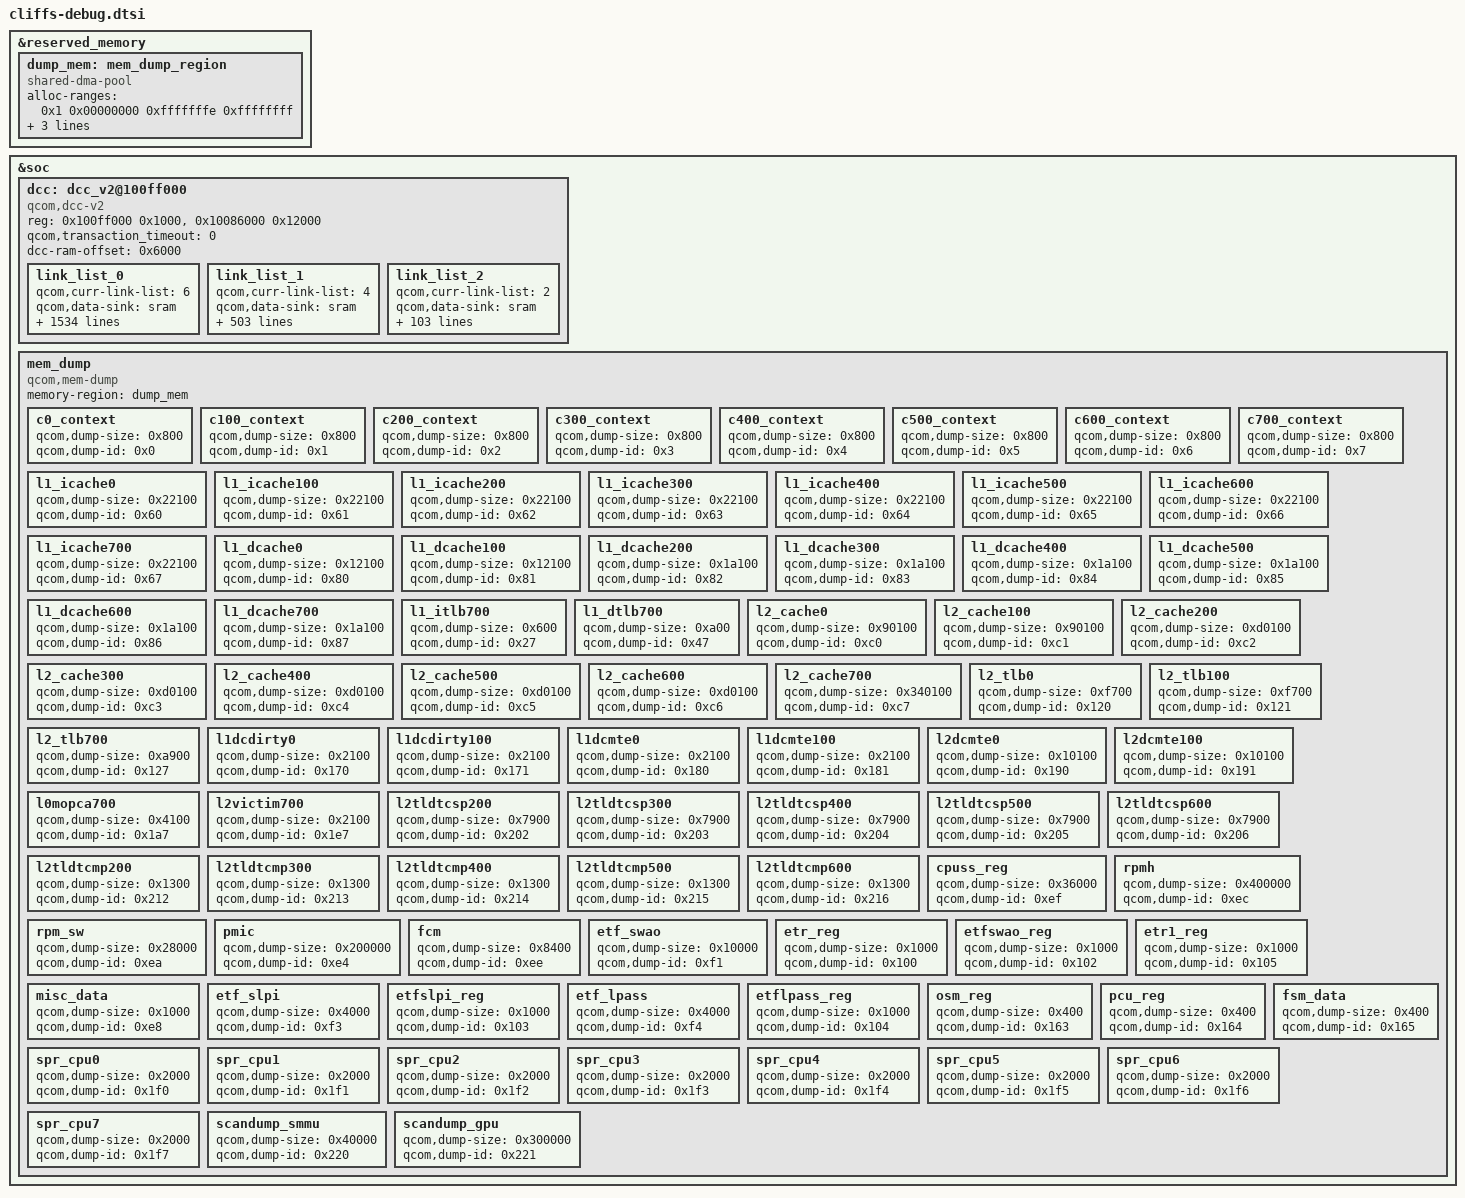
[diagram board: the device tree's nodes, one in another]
#include <dt-bindings/soc/qcom,dcc_v2.h>

&reserved_memory {
	#address-cells = <2>;
	#size-cells = <2>;
	ranges;

	dump_mem: mem_dump_region {
		compatible = "shared-dma-pool";
		alloc-ranges = <0x1 0x00000000 0xfffffffe 0xffffffff>;
		reusable;
		alignment = <0x0 0x400000>;
		size = <0 0x1800000>;
	};
};

&soc {
	dcc: dcc_v2@100ff000 {
		compatible = "qcom,dcc-v2";
		reg = <0x100ff000 0x1000>,
		      <0x10086000 0x12000>;

		qcom,transaction_timeout = <0>;

		reg-names = "dcc-base", "dcc-ram-base";
		dcc-ram-offset = <0x6000>;
		link_list_0 {
			qcom,curr-link-list = <6>;
			qcom,data-sink = "sram";
			qcom,ap-qad-override;
			qcom,link-list = <DCC_READ 0x17421000 2 0>,
				<DCC_READ 0x68c020c 2 0>,
				<DCC_READ 0x68c0228 3 0>,
				<DCC_READ 0x68c0248 3 0>,
				<DCC_READ 0x68c0268 3 0>,
				<DCC_READ 0x68c0288 3 0>,
				<DCC_READ 0x68c02a8 3 0>,
				<DCC_READ 0x68c0404 2 0>,
				<DCC_READ 0x720020c 2 0>,
				<DCC_READ 0x7200228 3 0>,
				<DCC_READ 0x7200248 3 0>,
				<DCC_READ 0x7200268 3 0>,
				<DCC_READ 0x7200288 3 0>,
				<DCC_READ 0x72002a8 3 0>,
				<DCC_READ 0x68c0110 1 0>,
				<DCC_READ 0x68c011c 1 0>,
				<DCC_READ 0x68c0208 1 0>,
				<DCC_READ 0x7200208 1 0>,
				<DCC_READ 0x320a4110 1 0>,
				<DCC_READ 0x320a411c 1 0>,
				<DCC_READ 0x320a4208 2 0>,
				<DCC_READ 0x320a4228 3 0>,
				<DCC_READ 0x320a4248 3 0>,
				<DCC_READ 0x320a4268 3 0>,
				<DCC_READ 0x320a4288 3 0>,
				<DCC_READ 0x320a42a8 3 0>,
				<DCC_READ 0x320a4400 3 0>,
				<DCC_READ 0x32302028 1 0>,
				<DCC_READ 0x323c0208 3 0>,
				<DCC_READ 0x323c0228 3 0>,
				<DCC_READ 0x323c0248 3 0>,
				<DCC_READ 0x323c0268 3 0>,
				<DCC_READ 0x323c0288 3 0>,
				<DCC_READ 0x323c02a8 3 0>,
				<DCC_READ 0x323c0400 3 0>,
				<DCC_READ 0x4080304 1 0>,
				<DCC_READ 0x4082028 1 0>,
				<DCC_READ 0x4140110 1 0>,
				<DCC_READ 0x414011c 1 0>,
				<DCC_READ 0x4140208 3 0>,
				<DCC_READ 0x4140228 3 0>,
				<DCC_READ 0x4140248 3 0>,
				<DCC_READ 0x4140268 3 0>,
				<DCC_READ 0x4140288 3 0>,
				<DCC_READ 0x41402a8 3 0>,
				<DCC_READ 0x4140400 3 0>,
				<DCC_READ 0x4200208 3 0>,
				<DCC_READ 0x4200228 3 0>,
				<DCC_READ 0x4200248 3 0>,
				<DCC_READ 0x4200268 3 0>,
				<DCC_READ 0x4200288 3 0>,
				<DCC_READ 0x42002a8 3 0>,
				<DCC_READ 0x4200400 3 0>,
				<DCC_READ 0x8a00304 1 0>,
				<DCC_READ 0x8a02028 1 0>,
				<DCC_READ 0x8ac011c 1 0>,
				<DCC_READ 0x8ac0208 3 0>,
				<DCC_READ 0x8ac0228 3 0>,
				<DCC_READ 0x8ac0248 3 0>,
				<DCC_READ 0x8ac0268 3 0>,
				<DCC_READ 0x8ac0288 3 0>,
				<DCC_READ 0x8ac02ac 2 0>,
				<DCC_READ 0x8ac02a8 1 0>,
				<DCC_READ 0x8ac0400 3 0>,
				<DCC_READ 0x8b00110 1 0>,
				<DCC_READ 0x6e0a100 1 0>,
				<DCC_READ 0x6e0a0ac 1 0>,
				<DCC_READ 0x6e0a0b0 1 0>,
				<DCC_READ 0x6e21104 1 0>,
				<DCC_READ 0x6e21108 1 0>,
				<DCC_READ 0x6e212ac 1 0>,
				<DCC_READ 0x6e212b0 1 0>,
				<DCC_READ 0x6e21300 1 0>,
				<DCC_READ 0x6e0a000 1 0>,
				<DCC_READ 0x7402048 1 0>,
				<DCC_READ 0x7402040 1 0>,
				<DCC_READ 0x1780005c 1 0>,
				<DCC_READ 0x1781005c 1 0>,
				<DCC_READ 0x1782005c 1 0>,
				<DCC_READ 0x1783005c 1 0>,
				<DCC_READ 0x1784005c 1 0>,
				<DCC_READ 0x1785005c 1 0>,
				<DCC_READ 0x1786005c 1 0>,
				<DCC_READ 0x1787005c 1 0>,
				<DCC_READ 0x1740003c 1 0>,
				<DCC_READ 0x17600238 1 0>,
				<DCC_READ 0x17600240 11 0>,
				<DCC_READ 0x17600274 1 0>,
				<DCC_READ 0x17600530 1 0>,
				<DCC_READ 0x1760051c 1 0>,
				<DCC_READ 0x17600524 1 0>,
				<DCC_READ 0x1760052c 1 0>,
				<DCC_READ 0x17600518 1 0>,
				<DCC_READ 0x17600520 1 0>,
				<DCC_READ 0x17600528 1 0>,
				<DCC_READ 0x17600404 4 0>,
				<DCC_READ 0x1760041c 4 0>,
				<DCC_READ 0x17600434 1 0>,
				<DCC_READ 0x1760043c 1 0>,
				<DCC_READ 0x17600440 1 0>,
				<DCC_READ 0x17400438 1 0>,
				<DCC_READ 0x17600044 1 0>,
				<DCC_READ 0x17600500 1 0>,
				<DCC_READ 0x221c209c 1 0>,
				<DCC_READ 0x17600504 5 0>,
				<DCC_READ 0x17900908 1 0>,
				<DCC_READ 0x17900c18 1 0>,
				<DCC_READ 0x17901908 1 0>,
				<DCC_READ 0x17901c18 1 0>,
				<DCC_READ 0x17b90810 3 0>,
				<DCC_READ 0x17b90c50 3 0>,
				<DCC_READ 0x17b93a04 2 0>,
				<DCC_READ 0x17ba0810 3 0>,
				<DCC_READ 0x17ba0c50 3 0>,
				<DCC_READ 0x17ba3a04 2 0>,
				<DCC_READ 0x17b93000 80 0>,
				<DCC_READ 0x17ba3000 80 0>,
				<DCC_READ 0x0c201244 1 0>,
				<DCC_READ 0x0c202244 1 0>,
				<DCC_READ 0x17b00000 1 0>,
				<DCC_READ 0x17a94030 1 0>,
				<DCC_READ 0x17a9408c 1 0>,
				<DCC_WRITE 0x17a9409c 0x78 0>,
				<DCC_WRITE 0x17a9409c 0x0 0>,
				<DCC_WRITE 0x17a94048 0x1 0>,
				<DCC_WRITE 0x17a94090 0x0 0>,
				<DCC_WRITE 0x17a94090 0x25 0>,
				<DCC_READ 0x17a94098 1 0>,
				<DCC_WRITE 0x17a94048 0x1d 0>,
				<DCC_WRITE 0x17a94090 0x0 0>,
				<DCC_WRITE 0x17a94090 0x25 0>,
				<DCC_READ 0x17a94098 1 0>,
				<DCC_READ 0x17a90030 1 0>,
				<DCC_READ 0x17a9008c 1 0>,
				<DCC_WRITE 0x17a9009c 0x78 0>,
				<DCC_WRITE 0x17a9009c 0x0 0>,
				<DCC_WRITE 0x17a90048 0x1 0>,
				<DCC_WRITE 0x17a90090 0x0 0>,
				<DCC_WRITE 0x17a90090 0x25 0>,
				<DCC_READ 0x17a90098 1 0>,
				<DCC_WRITE 0x17a90048 0x1d 0>,
				<DCC_WRITE 0x17a90090 0x0 0>,
				<DCC_WRITE 0x17a90090 0x25 0>,
				<DCC_READ 0x17a90098 1 0>,
				<DCC_READ 0x17a92030 1 0>,
				<DCC_READ 0x17a9208c 1 0>,
				<DCC_WRITE 0x17a9209c 0x78 0>,
				<DCC_WRITE 0x17a9209c 0x0 0>,
				<DCC_WRITE 0x17a92048 0x1 0>,
				<DCC_WRITE 0x17a92090 0x0 0>,
				<DCC_WRITE 0x17a92090 0x25 0>,
				<DCC_READ 0x17a92098 1 0>,
				<DCC_WRITE 0x17a92048 0x1d 0>,
				<DCC_WRITE 0x17a92090 0x0 0>,
				<DCC_WRITE 0x17a92090 0x25 0>,
				<DCC_READ 0x17a92098 1 0>,
				<DCC_READ 0x17a96030 1 0>,
				<DCC_READ 0x17a9608c 1 0>,
				<DCC_WRITE 0x17a9609c 0x78 0>,
				<DCC_WRITE 0x17a9609c 0x0 0>,
				<DCC_WRITE 0x17a96048 0x1 0>,
				<DCC_WRITE 0x17a96090 0x0 0>,
				<DCC_WRITE 0x17a96090 0x25 0>,
				<DCC_READ 0x17a96098 1 0>,
				<DCC_WRITE 0x17a96048 0x1d 0>,
				<DCC_WRITE 0x17a96090 0x0 0>,
				<DCC_WRITE 0x17a96090 0x25 0>,
				<DCC_READ 0x17a96098 1 0>,
				<DCC_READ 0x17d98024 1 0>,
				<DCC_READ 0x13822000 1 1>,
				<DCC_READ 0x221c20a4 1 0>,
				<DCC_READ 0x01fc8000 1 0>,
				<DCC_READ 0x17400038 1 0>,
				<DCC_READ 0x17d91020 1 0>,
				<DCC_READ 0x17d92020 1 0>,
				<DCC_READ 0x17d93020 1 0>,
				<DCC_READ 0x17d90020 1 0>,
				<DCC_READ 0x17d9134c 1 0>,
				<DCC_READ 0x17d9234c 1 0>,
				<DCC_READ 0x17d9334c 1 0>,
				<DCC_READ 0x17d9034c 1 0>,
				<DCC_READ 0x17d91300 1 0>,
				<DCC_READ 0x17d92300 1 0>,
				<DCC_READ 0x17d93300 1 0>,
				<DCC_READ 0x17d90300 1 0>,
				<DCC_READ 0x24183040 1 0>,
				<DCC_READ 0x24183048 1 0>,
				<DCC_READ 0x24102010 1 0>,
				<DCC_READ 0x24102020 6 0>,
				<DCC_READ 0x24102410 1 0>,
				<DCC_READ 0x24102420 6 0>,
				<DCC_READ 0x24142010 1 0>,
				<DCC_READ 0x24142020 6 0>,
				<DCC_READ 0x24142410 1 0>,
				<DCC_READ 0x24142420 6 0>,
				<DCC_READ 0x24182010 1 0>,
				<DCC_READ 0x24182020 6 0>,
				<DCC_READ 0x24182410 1 0>,
				<DCC_READ 0x24182420 6 0>,
				<DCC_READ 0x24102810 1 0>,
				<DCC_READ 0x24102820 1 0>,
				<DCC_READ 0x24102828 2 0>,
				<DCC_READ 0x24102C10 1 0>,
				<DCC_READ 0x24102C20 1 0>,
				<DCC_READ 0x24102C28 2 0>,
				<DCC_READ 0x24142810 1 0>,
				<DCC_READ 0x24142820 1 0>,
				<DCC_READ 0x24142828 2 0>,
				<DCC_READ 0x24142C10 1 0>,
				<DCC_READ 0x24142C20 1 0>,
				<DCC_READ 0x24142C28 2 0>,
				<DCC_READ 0x24100810 1 0>,
				<DCC_READ 0x24100838 1 0>,
				<DCC_READ 0x24100830 2 0>,
				<DCC_READ 0x24100830 2 0>,
				<DCC_READ 0x24100830 2 0>,
				<DCC_READ 0x24100830 2 0>,
				<DCC_READ 0x24100838 1 0>,
				<DCC_READ 0x24100830 2 0>,
				<DCC_READ 0x24100830 2 0>,
				<DCC_READ 0x24100830 2 0>,
				<DCC_READ 0x24100830 2 0>,
				<DCC_READ 0x24100838 1 0>,
				<DCC_READ 0x24100830 2 0>,
				<DCC_READ 0x24100830 2 0>,
				<DCC_READ 0x24100830 2 0>,
				<DCC_READ 0x24100830 2 0>,
				<DCC_READ 0x24100838 1 0>,
				<DCC_READ 0x24100830 2 0>,
				<DCC_READ 0x24100830 2 0>,
				<DCC_READ 0x24100830 2 0>,
				<DCC_READ 0x24100830 2 0>,
				<DCC_READ 0x24100808 2 0>,
				<DCC_READ 0x24100c10 1 0>,
				<DCC_READ 0x24100c38 1 0>,
				<DCC_READ 0x24100c30 2 0>,
				<DCC_READ 0x24100c30 2 0>,
				<DCC_READ 0x24100c30 2 0>,
				<DCC_READ 0x24100c30 2 0>,
				<DCC_READ 0x24100c38 1 0>,
				<DCC_READ 0x24100c30 2 0>,
				<DCC_READ 0x24100c30 2 0>,
				<DCC_READ 0x24100c30 2 0>,
				<DCC_READ 0x24100c30 2 0>,
				<DCC_READ 0x24100c38 1 0>,
				<DCC_READ 0x24100c30 2 0>,
				<DCC_READ 0x24100c30 2 0>,
				<DCC_READ 0x24100c30 2 0>,
				<DCC_READ 0x24100c30 2 0>,
				<DCC_READ 0x24100c38 1 0>,
				<DCC_READ 0x24100c30 2 0>,
				<DCC_READ 0x24100c30 2 0>,
				<DCC_READ 0x24100c30 2 0>,
				<DCC_READ 0x24100c30 2 0>,
				<DCC_READ 0x24100c08 2 0>,
				<DCC_READ 0x24140810 1 0>,
				<DCC_READ 0x24140838 1 0>,
				<DCC_READ 0x24140830 2 0>,
				<DCC_READ 0x24140830 2 0>,
				<DCC_READ 0x24140830 2 0>,
				<DCC_READ 0x24140830 2 0>,
				<DCC_READ 0x24140838 1 0>,
				<DCC_READ 0x24140830 2 0>,
				<DCC_READ 0x24140830 2 0>,
				<DCC_READ 0x24140830 2 0>,
				<DCC_READ 0x24140830 2 0>,
				<DCC_READ 0x24140838 1 0>,
				<DCC_READ 0x24140830 2 0>,
				<DCC_READ 0x24140830 2 0>,
				<DCC_READ 0x24140830 2 0>,
				<DCC_READ 0x24140830 2 0>,
				<DCC_READ 0x24140838 1 0>,
				<DCC_READ 0x24140830 2 0>,
				<DCC_READ 0x24140830 2 0>,
				<DCC_READ 0x24140830 2 0>,
				<DCC_READ 0x24140830 2 0>,
				<DCC_READ 0x24140808 2 0>,
				<DCC_READ 0x24140c10 1 0>,
				<DCC_READ 0x24140c38 1 0>,
				<DCC_READ 0x24140c30 2 0>,
				<DCC_READ 0x24140c30 2 0>,
				<DCC_READ 0x24140c30 2 0>,
				<DCC_READ 0x24140c30 2 0>,
				<DCC_READ 0x24140c38 1 0>,
				<DCC_READ 0x24140c30 2 0>,
				<DCC_READ 0x24140c30 2 0>,
				<DCC_READ 0x24140c30 2 0>,
				<DCC_READ 0x24140c30 2 0>,
				<DCC_READ 0x24140c38 1 0>,
				<DCC_READ 0x24140c30 2 0>,
				<DCC_READ 0x24140c30 2 0>,
				<DCC_READ 0x24140c30 2 0>,
				<DCC_READ 0x24140c30 2 0>,
				<DCC_READ 0x24140c38 1 0>,
				<DCC_READ 0x24140c30 2 0>,
				<DCC_READ 0x24140c30 2 0>,
				<DCC_READ 0x24140c30 2 0>,
				<DCC_READ 0x24140c30 2 0>,
				<DCC_READ 0x24140c08 2 0>,
				<DCC_READ 0x24180010 1 0>,
				<DCC_READ 0x24180038 1 0>,
				<DCC_READ 0x24180030 2 0>,
				<DCC_READ 0x24180030 2 0>,
				<DCC_READ 0x24180030 2 0>,
				<DCC_READ 0x24180030 2 0>,
				<DCC_READ 0x24180038 1 0>,
				<DCC_READ 0x24180030 2 0>,
				<DCC_READ 0x24180030 2 0>,
				<DCC_READ 0x24180030 2 0>,
				<DCC_READ 0x24180030 2 0>,
				<DCC_READ 0x24180038 1 0>,
				<DCC_READ 0x24180030 2 0>,
				<DCC_READ 0x24180030 2 0>,
				<DCC_READ 0x24180030 2 0>,
				<DCC_READ 0x24180030 2 0>,
				<DCC_READ 0x24180038 1 0>,
				<DCC_READ 0x24180030 2 0>,
				<DCC_READ 0x24180030 2 0>,
				<DCC_READ 0x24180030 2 0>,
				<DCC_READ 0x24180030 2 0>,
				<DCC_READ 0x24180008 2 0>,
				<DCC_READ 0x24180410 1 0>,
				<DCC_READ 0x24180438 1 0>,
				<DCC_READ 0x24180430 2 0>,
				<DCC_READ 0x24180430 2 0>,
				<DCC_READ 0x24180430 2 0>,
				<DCC_READ 0x24180430 2 0>,
				<DCC_READ 0x24180438 1 0>,
				<DCC_READ 0x24180430 2 0>,
				<DCC_READ 0x24180430 2 0>,
				<DCC_READ 0x24180430 2 0>,
				<DCC_READ 0x24180430 2 0>,
				<DCC_READ 0x24180438 1 0>,
				<DCC_READ 0x24180430 2 0>,
				<DCC_READ 0x24180430 2 0>,
				<DCC_READ 0x24180430 2 0>,
				<DCC_READ 0x24180430 2 0>,
				<DCC_READ 0x24180438 1 0>,
				<DCC_READ 0x24180430 2 0>,
				<DCC_READ 0x24180430 2 0>,
				<DCC_READ 0x24180430 2 0>,
				<DCC_READ 0x24180430 2 0>,
				<DCC_READ 0x24180408 2 0>,
				<DCC_READ 0x24101000 3 0>,
				<DCC_READ 0x24101010 2 0>,
				<DCC_READ 0x24101010 2 0>,
				<DCC_READ 0x24101018 1 0>,
				<DCC_READ 0x24101080 1 0>,
				<DCC_READ 0x24101084 2 0>,
				<DCC_LOOP 0x5 0 0>,
				<DCC_READ 0x24101090 2 0>,
				<DCC_LOOP 0x1 0 0>,
				<DCC_READ 0x24101098 1 0>,
				<DCC_READ 0x24141000 1 0>,
				<DCC_READ 0x24141004 2 0>,
				<DCC_READ 0x24141010 2 0>,
				<DCC_READ 0x24141010 2 0>,
				<DCC_READ 0x24141018 1 0>,
				<DCC_READ 0x24141080 1 0>,
				<DCC_READ 0x24141084 1 0>,
				<DCC_LOOP 0x5 0 0>,
				<DCC_READ 0x24141090 2 0>,
				<DCC_LOOP 0x1 0 0>,
				<DCC_READ 0x24141098 1 0>,
				<DCC_READ 0x24181000 1 0>,
				<DCC_READ 0x24181004 2 0>,
				<DCC_READ 0x24181010 2 0>,
				<DCC_READ 0x24181010 2 0>,
				<DCC_READ 0x24181018 1 0>,
				<DCC_READ 0x24181080 1 0>,
				<DCC_READ 0x24181084 2 0>,
				<DCC_LOOP 0xb 0 0>,
				<DCC_READ 0x24181090 2 0>,
				<DCC_LOOP 0x1 0 0>,
				<DCC_READ 0x24181098 1 0>,
				<DCC_READ 0x24131010 1 0>,
				<DCC_READ 0x24133010 1 0>,
				<DCC_READ 0x24135010 1 0>,
				<DCC_READ 0x24137010 1 0>,
				<DCC_READ 0x24138010 1 0>,
				<DCC_READ 0x24139010 1 0>,
				<DCC_READ 0x24171010 1 0>,
				<DCC_READ 0x24173010 1 0>,
				<DCC_READ 0x24175010 1 0>,
				<DCC_READ 0x24177010 1 0>,
				<DCC_READ 0x24178010 1 0>,
				<DCC_READ 0x24179010 1 0>,
				<DCC_READ 0x241b1010 1 0>,
				<DCC_READ 0x241b3010 1 0>,
				<DCC_READ 0x241b5010 1 0>,
				<DCC_READ 0x241b7010 1 0>,
				<DCC_READ 0x241b9010 1 0>,
				<DCC_READ 0x241bb010 1 0>,
				<DCC_READ 0x241bc010 1 0>,
				<DCC_READ 0x241bd010 1 0>,
				<DCC_READ 0x241bf010 1 0>,
				<DCC_READ 0x241c1010 1 0>,
				<DCC_READ 0x241c3010 1 0>,
				<DCC_WRITE 0x24100828 0x2 0>,
				<DCC_LOOP 0x40 0 0>,
				<DCC_READ 0x24100830 2 0>,
				<DCC_READ 0x24100830 2 0>,
				<DCC_READ 0x24100830 2 0>,
				<DCC_READ 0x24100830 2 0>,
				<DCC_LOOP 0x1 0 0>,
				<DCC_WRITE 0x24100828 0x1 0>,
				<DCC_WRITE 0x24100c28 0x2 0>,
				<DCC_LOOP 0x40 0 0>,
				<DCC_READ 0x24100c30 2 0>,
				<DCC_READ 0x24100c30 2 0>,
				<DCC_READ 0x24100c30 2 0>,
				<DCC_READ 0x24100c30 2 0>,
				<DCC_LOOP 0x1 0 0>,
				<DCC_WRITE 0x24100c28 0x1 0>,
				<DCC_WRITE 0x24140828 0x2 0>,
				<DCC_LOOP 0x40 0 0>,
				<DCC_READ 0x24140830 2 0>,
				<DCC_READ 0x24140830 2 0>,
				<DCC_READ 0x24140830 2 0>,
				<DCC_READ 0x24140830 2 0>,
				<DCC_LOOP 0x1 0 0>,
				<DCC_WRITE 0x24140828 0x1 0>,
				<DCC_WRITE 0x24140c28 0x2 0>,
				<DCC_LOOP 0x40 0 0>,
				<DCC_READ 0x24140c30 2 0>,
				<DCC_READ 0x24140c30 2 0>,
				<DCC_READ 0x24140c30 2 0>,
				<DCC_READ 0x24140c30 2 0>,
				<DCC_LOOP 0x1 0 0>,
				<DCC_WRITE 0x24140c28 0x1 0>,
				<DCC_READ 0x17810024 1 0>,
				<DCC_READ 0x17810038 6 0>,
				<DCC_READ 0x17810058 4 0>,
				<DCC_READ 0x1781006c 1 0>,
				<DCC_READ 0x178100f0 2 0>,
				<DCC_READ 0x17820010 1 0>,
				<DCC_READ 0x17820024 1 0>,
				<DCC_READ 0x17820038 6 0>,
				<DCC_READ 0x17820058 4 0>,
				<DCC_READ 0x178200f0 2 0>,
				<DCC_READ 0x17830010 1 0>,
				<DCC_READ 0x17830024 1 0>,
				<DCC_READ 0x17830038 6 0>,
				<DCC_READ 0x17830058 4 0>,
				<DCC_READ 0x178300f0 2 0>,
				<DCC_READ 0x17840010 1 0>,
				<DCC_READ 0x17840024 1 0>,
				<DCC_READ 0x17840038 6 0>,
				<DCC_READ 0x17840058 4 0>,
				<DCC_READ 0x178400f0 2 0>,
				<DCC_READ 0x17850010 1 0>,
				<DCC_READ 0x17850024 1 0>,
				<DCC_READ 0x17850038 6 0>,
				<DCC_READ 0x17850058 4 0>,
				<DCC_READ 0x178500f0 2 0>,
				<DCC_READ 0x17860010 1 0>,
				<DCC_READ 0x17860024 1 0>,
				<DCC_READ 0x17860038 6 0>,
				<DCC_READ 0x17860058 4 0>,
				<DCC_READ 0x178600f0 2 0>,
				<DCC_READ 0x17870010 1 0>,
				<DCC_READ 0x17870024 1 0>,
				<DCC_READ 0x17870038 6 0>,
				<DCC_READ 0x17870058 4 0>,
				<DCC_READ 0x178700f0 2 0>,
				<DCC_READ 0x17880010 1 0>,
				<DCC_READ 0x17880024 1 0>,
				<DCC_READ 0x17880038 6 0>,
				<DCC_READ 0x17890010 1 0>,
				<DCC_READ 0x17890024 1 0>,
				<DCC_READ 0x17890038 6 0>,
				<DCC_READ 0x178b0010 1 0>,
				<DCC_READ 0x178b0024 1 0>,
				<DCC_READ 0x178b0038 6 0>,
				<DCC_READ 0x178b006c 5 0>,
				<DCC_READ 0x178b0084 1 0>,
				<DCC_READ 0x178b00f4 5 0>,
				<DCC_READ 0x178b0118 9 0>,
				<DCC_READ 0x178b0158 5 0>,
				<DCC_READ 0x178b0170 2 0>,
				<DCC_READ 0x178b0188 5 0>,
				<DCC_READ 0x178b01ac 6 0>,
				<DCC_READ 0x178b01c8 1 0>,
				<DCC_READ 0x178b0204 1 0>,
				<DCC_READ 0x178b0244 1 0>,
				<DCC_READ 0x17e30000 1 0>,
				<DCC_READ 0x17e30008 1 0>,
				<DCC_READ 0x17e30010 1 0>,
				<DCC_READ 0x17e80000 1 0>,
				<DCC_READ 0x17e80008 1 0>,
				<DCC_READ 0x17e80010 1 0>,
				<DCC_READ 0x17f80000 1 0>,
				<DCC_READ 0x17f80008 1 0>,
				<DCC_READ 0x17f80010 1 0>,
				<DCC_READ 0x18080000 1 0>,
				<DCC_READ 0x18080008 1 0>,
				<DCC_READ 0x18080010 1 0>,
				<DCC_READ 0x18180000 1 0>,
				<DCC_READ 0x18180008 1 0>,
				<DCC_READ 0x18180010 1 0>,
				<DCC_READ 0x18280000 1 0>,
				<DCC_READ 0x18280008 1 0>,
				<DCC_READ 0x18280010 1 0>,
				<DCC_READ 0x18380000 1 0>,
				<DCC_READ 0x18380008 1 0>,
				<DCC_READ 0x18380010 1 0>,
				<DCC_READ 0x18480000 1 0>,
				<DCC_READ 0x18480008 1 0>,
				<DCC_READ 0x18480010 1 0>,
				<DCC_READ 0x18580000 1 0>,
				<DCC_READ 0x18580008 1 0>,
				<DCC_READ 0x18580010 1 0>,
				<DCC_READ 0x2407701c 1 0>,
				<DCC_READ 0x24077030 1 0>,
				<DCC_READ 0x2408005c 1 0>,
				<DCC_READ 0x240800c8 1 0>,
				<DCC_READ 0x240800d4 1 0>,
				<DCC_READ 0x240800e0 1 0>,
				<DCC_READ 0x240800ec 1 0>,
				<DCC_READ 0x240800f8 1 0>,
				<DCC_READ 0x240801b4 1 0>,
				<DCC_READ 0x240a8120 5 0>,
				<DCC_READ 0x240a8144 2 0>,
				<DCC_READ 0x240a81d0 4 0>,
				<DCC_READ 0x240a81f0 1 0>,
				<DCC_READ 0x240a81fc 1 0>,
				<DCC_READ 0x240a8208 1 0>,
				<DCC_READ 0x240a8214 1 0>,
				<DCC_READ 0x240a8264 1 0>,
				<DCC_READ 0x240a8284 1 0>,
				<DCC_READ 0x240a82fc 1 0>,
				<DCC_READ 0x240a8860 3 0>,
				<DCC_READ 0x240aa034 3 0>,
				<DCC_READ 0x240ba28c 1 0>,
				<DCC_READ 0x240ba294 1 0>,
				<DCC_READ 0x240ba29c 1 0>,
				<DCC_READ 0x24185100 4 0>,
				<DCC_READ 0x24187100 1 0>,
				<DCC_READ 0x2418c100 1 0>,
				<DCC_READ 0x24401e64 1 0>,
				<DCC_READ 0x24401ea0 1 0>,
				<DCC_READ 0x24403e64 1 0>,
				<DCC_READ 0x24403ea0 1 0>,
				<DCC_READ 0x2440527c 1 0>,
				<DCC_READ 0x24405290 1 0>,
				<DCC_READ 0x244054ec 1 0>,
				<DCC_READ 0x244054f4 1 0>,
				<DCC_READ 0x24405514 1 0>,
				<DCC_READ 0x2440551c 1 0>,
				<DCC_READ 0x24405524 1 0>,
				<DCC_READ 0x24405548 1 0>,
				<DCC_READ 0x24405550 1 0>,
				<DCC_READ 0x24405558 1 0>,
				<DCC_READ 0x244055b8 1 0>,
				<DCC_READ 0x244055c0 1 0>,
				<DCC_READ 0x244055ec 1 0>,
				<DCC_READ 0x24405870 1 0>,
				<DCC_READ 0x244058a0 1 0>,
				<DCC_READ 0x244058a8 1 0>,
				<DCC_READ 0x244058b0 1 0>,
				<DCC_READ 0x244058b8 1 0>,
				<DCC_READ 0x244058d8 2 0>,
				<DCC_READ 0x244058f4 1 0>,
				<DCC_READ 0x244058fc 1 0>,
				<DCC_READ 0x24405920 1 0>,
				<DCC_READ 0x24405928 1 0>,
				<DCC_READ 0x24405944 1 0>,
				<DCC_READ 0x24406604 1 0>,
				<DCC_READ 0x2440660c 1 0>,
				<DCC_READ 0x24440310 1 0>,
				<DCC_READ 0x24440400 2 0>,
				<DCC_READ 0x24440410 3 0>,
				<DCC_READ 0x24440428 1 0>,
				<DCC_READ 0x24440430 1 0>,
				<DCC_READ 0x24440440 1 0>,
				<DCC_READ 0x24440448 1 0>,
				<DCC_READ 0x244404a0 1 0>,
				<DCC_READ 0x244404b0 3 0>,
				<DCC_READ 0x244404d0 2 0>,
				<DCC_READ 0x2444341c 1 0>,
				<DCC_READ 0x24445804 1 0>,
				<DCC_READ 0x2444590c 1 0>,
				<DCC_READ 0x24445a14 1 0>,
				<DCC_READ 0x24445c1c 1 0>,
				<DCC_READ 0x24445c38 1 0>,
				<DCC_READ 0x24449100 1 0>,
				<DCC_READ 0x24449110 1 0>,
				<DCC_READ 0x24449120 1 0>,
				<DCC_READ 0x24449180 2 0>,
				<DCC_READ 0x24460618 1 0>,
				<DCC_READ 0x24460684 1 0>,
				<DCC_READ 0x2446068c 1 0>,
				<DCC_READ 0x24481e64 1 0>,
				<DCC_READ 0x24481ea0 1 0>,
				<DCC_READ 0x24483e64 1 0>,
				<DCC_READ 0x24483ea0 1 0>,
				<DCC_READ 0x2448527c 1 0>,
				<DCC_READ 0x24485290 1 0>,
				<DCC_READ 0x244854ec 1 0>,
				<DCC_READ 0x244854f4 1 0>,
				<DCC_READ 0x24485514 1 0>,
				<DCC_READ 0x2448551c 1 0>,
				<DCC_READ 0x24485524 1 0>,
				<DCC_READ 0x24485548 1 0>,
				<DCC_READ 0x24485550 1 0>,
				<DCC_READ 0x24485558 1 0>,
				<DCC_READ 0x244855b8 1 0>,
				<DCC_READ 0x244855c0 1 0>,
				<DCC_READ 0x244855ec 1 0>,
				<DCC_READ 0x24485870 1 0>,
				<DCC_READ 0x244858a0 1 0>,
				<DCC_READ 0x244858a8 1 0>,
				<DCC_READ 0x244858b0 1 0>,
				<DCC_READ 0x244858b8 1 0>,
				<DCC_READ 0x244858d8 2 0>,
				<DCC_READ 0x244858f4 1 0>,
				<DCC_READ 0x244858fc 1 0>,
				<DCC_READ 0x24485920 1 0>,
				<DCC_READ 0x24485928 1 0>,
				<DCC_READ 0x24485944 1 0>,
				<DCC_READ 0x24486604 1 0>,
				<DCC_READ 0x2448660c 1 0>,
				<DCC_READ 0x244c0310 1 0>,
				<DCC_READ 0x244c0400 2 0>,
				<DCC_READ 0x244c0410 3 0>,
				<DCC_READ 0x244c0428 1 0>,
				<DCC_READ 0x244c0430 1 0>,
				<DCC_READ 0x244c0440 1 0>,
				<DCC_READ 0x244c0448 1 0>,
				<DCC_READ 0x244c04a0 1 0>,
				<DCC_READ 0x244c04b0 3 0>,
				<DCC_READ 0x244c04d0 2 0>,
				<DCC_READ 0x244c341c 1 0>,
				<DCC_READ 0x244c5804 1 0>,
				<DCC_READ 0x244c590c 1 0>,
				<DCC_READ 0x244c5a14 1 0>,
				<DCC_READ 0x244c5c1c 1 0>,
				<DCC_READ 0x244c5c38 1 0>,
				<DCC_READ 0x244c9100 1 0>,
				<DCC_READ 0x244c9110 1 0>,
				<DCC_READ 0x244c9120 1 0>,
				<DCC_READ 0x244c9180 2 0>,
				<DCC_READ 0x244e0618 1 0>,
				<DCC_READ 0x244e0684 1 0>,
				<DCC_READ 0x244e068c 1 0>,
				<DCC_READ 0x24601e64 1 0>,
				<DCC_READ 0x24601ea0 1 0>,
				<DCC_READ 0x24603e64 1 0>,
				<DCC_READ 0x24603ea0 1 0>,
				<DCC_READ 0x2460527c 1 0>,
				<DCC_READ 0x24605290 1 0>,
				<DCC_READ 0x246054ec 1 0>,
				<DCC_READ 0x246054f4 1 0>,
				<DCC_READ 0x24605514 1 0>,
				<DCC_READ 0x2460551c 1 0>,
				<DCC_READ 0x24605524 1 0>,
				<DCC_READ 0x24605548 1 0>,
				<DCC_READ 0x24605550 1 0>,
				<DCC_READ 0x24605558 1 0>,
				<DCC_READ 0x246055b8 1 0>,
				<DCC_READ 0x246055c0 1 0>,
				<DCC_READ 0x246055ec 1 0>,
				<DCC_READ 0x24605870 1 0>,
				<DCC_READ 0x246058a0 1 0>,
				<DCC_READ 0x246058a8 1 0>,
				<DCC_READ 0x246058b0 1 0>,
				<DCC_READ 0x246058b8 1 0>,
				<DCC_READ 0x246058d8 2 0>,
				<DCC_READ 0x246058f4 1 0>,
				<DCC_READ 0x246058fc 1 0>,
				<DCC_READ 0x24605920 1 0>,
				<DCC_READ 0x24605928 1 0>,
				<DCC_READ 0x24605944 1 0>,
				<DCC_READ 0x24606604 1 0>,
				<DCC_READ 0x2460660c 1 0>,
				<DCC_READ 0x24640310 1 0>,
				<DCC_READ 0x24640400 2 0>,
				<DCC_READ 0x24640410 3 0>,
				<DCC_READ 0x24640428 1 0>,
				<DCC_READ 0x24640430 1 0>,
				<DCC_READ 0x24640440 1 0>,
				<DCC_READ 0x24640448 1 0>,
				<DCC_READ 0x246404a0 1 0>,
				<DCC_READ 0x246404b0 3 0>,
				<DCC_READ 0x246404d0 2 0>,
				<DCC_READ 0x2464341c 1 0>,
				<DCC_READ 0x24645804 1 0>,
				<DCC_READ 0x2464590c 1 0>,
				<DCC_READ 0x24645a14 1 0>,
				<DCC_READ 0x24645c1c 1 0>,
				<DCC_READ 0x24645c38 1 0>,
				<DCC_READ 0x24649100 1 0>,
				<DCC_READ 0x24649110 1 0>,
				<DCC_READ 0x24649120 1 0>,
				<DCC_READ 0x24649180 2 0>,
				<DCC_READ 0x24660618 1 0>,
				<DCC_READ 0x24660684 1 0>,
				<DCC_READ 0x2466068c 1 0>,
				<DCC_READ 0x24681e64 1 0>,
				<DCC_READ 0x24681ea0 1 0>,
				<DCC_READ 0x24683e64 1 0>,
				<DCC_READ 0x24683ea0 1 0>,
				<DCC_READ 0x2468527c 1 0>,
				<DCC_READ 0x24685290 1 0>,
				<DCC_READ 0x246854ec 1 0>,
				<DCC_READ 0x246854f4 1 0>,
				<DCC_READ 0x24685514 1 0>,
				<DCC_READ 0x2468551c 1 0>,
				<DCC_READ 0x24685524 1 0>,
				<DCC_READ 0x24685548 1 0>,
				<DCC_READ 0x24685550 1 0>,
				<DCC_READ 0x24685558 1 0>,
				<DCC_READ 0x246855b8 1 0>,
				<DCC_READ 0x246855c0 1 0>,
				<DCC_READ 0x246855ec 1 0>,
				<DCC_READ 0x24685870 1 0>,
				<DCC_READ 0x246858a0 1 0>,
				<DCC_READ 0x246858a8 1 0>,
				<DCC_READ 0x246858b0 1 0>,
				<DCC_READ 0x246858b8 1 0>,
				<DCC_READ 0x246858d8 2 0>,
				<DCC_READ 0x246858f4 1 0>,
				<DCC_READ 0x246858fc 1 0>,
				<DCC_READ 0x24685920 1 0>,
				<DCC_READ 0x24685928 1 0>,
				<DCC_READ 0x24685944 1 0>,
				<DCC_READ 0x24686604 1 0>,
				<DCC_READ 0x2468660c 1 0>,
				<DCC_READ 0x246c0310 1 0>,
				<DCC_READ 0x246c0400 2 0>,
				<DCC_READ 0x246c0410 3 0>,
				<DCC_READ 0x246c0428 1 0>,
				<DCC_READ 0x246c0430 1 0>,
				<DCC_READ 0x246c0440 1 0>,
				<DCC_READ 0x246c0448 1 0>,
				<DCC_READ 0x246c04a0 1 0>,
				<DCC_READ 0x246c04b0 3 0>,
				<DCC_READ 0x246c04d0 2 0>,
				<DCC_READ 0x246c341c 1 0>,
				<DCC_READ 0x246c5804 1 0>,
				<DCC_READ 0x246c590c 1 0>,
				<DCC_READ 0x246c5a14 1 0>,
				<DCC_READ 0x246c5c1c 1 0>,
				<DCC_READ 0x246c5c38 1 0>,
				<DCC_READ 0x246c9100 1 0>,
				<DCC_READ 0x246c9110 1 0>,
				<DCC_READ 0x246c9120 1 0>,
				<DCC_READ 0x246c9180 2 0>,
				<DCC_READ 0x246e0618 1 0>,
				<DCC_READ 0x246e0684 1 0>,
				<DCC_READ 0x246e068c 1 0>,
				<DCC_READ 0x24840310 1 0>,
				<DCC_READ 0x24840400 2 0>,
				<DCC_READ 0x24840410 3 0>,
				<DCC_READ 0x24840428 1 0>,
				<DCC_READ 0x24840430 1 0>,
				<DCC_READ 0x24840440 1 0>,
				<DCC_READ 0x24840448 1 0>,
				<DCC_READ 0x248404a0 1 0>,
				<DCC_READ 0x248404b0 3 0>,
				<DCC_READ 0x248404d0 2 0>,
				<DCC_READ 0x2484341c 1 0>,
				<DCC_READ 0x24845804 1 0>,
				<DCC_READ 0x2484590c 1 0>,
				<DCC_READ 0x24845a14 1 0>,
				<DCC_READ 0x24845c1c 1 0>,
				<DCC_READ 0x24845c38 1 0>,
				<DCC_READ 0x24849100 1 0>,
				<DCC_READ 0x24849110 1 0>,
				<DCC_READ 0x24849120 1 0>,
				<DCC_READ 0x24849180 2 0>,
				<DCC_READ 0x24860618 1 0>,
				<DCC_READ 0x24860684 1 0>,
				<DCC_READ 0x2486068c 1 0>,
				<DCC_READ 0x248c0310 1 0>,
				<DCC_READ 0x248c0400 2 0>,
				<DCC_READ 0x248c0410 3 0>,
				<DCC_READ 0x248c0428 1 0>,
				<DCC_READ 0x248c0430 1 0>,
				<DCC_READ 0x248c0440 1 0>,
				<DCC_READ 0x248c0448 1 0>,
				<DCC_READ 0x248c04a0 1 0>,
				<DCC_READ 0x248c04b0 3 0>,
				<DCC_READ 0x248c04d0 2 0>,
				<DCC_READ 0x248c341c 1 0>,
				<DCC_READ 0x248c5804 1 0>,
				<DCC_READ 0x248c590c 1 0>,
				<DCC_READ 0x248c5a14 1 0>,
				<DCC_READ 0x248c5c1c 1 0>,
				<DCC_READ 0x248c5c38 1 0>,
				<DCC_READ 0x248c9100 1 0>,
				<DCC_READ 0x248c9110 1 0>,
				<DCC_READ 0x248c9120 1 0>,
				<DCC_READ 0x248c9180 2 0>,
				<DCC_READ 0x248e0618 1 0>,
				<DCC_READ 0x248e0684 1 0>,
				<DCC_READ 0x248e068c 1 0>,
				<DCC_READ 0x25020348 1 0>,
				<DCC_READ 0x25020480 1 0>,
				<DCC_READ 0x25022400 1 0>,
				<DCC_READ 0x25023220 4 0>,
				<DCC_READ 0x25023308 1 0>,
				<DCC_READ 0x25023318 1 0>,
				<DCC_READ 0x25038100 1 0>,
				<DCC_READ 0x2503c030 1 0>,
				<DCC_READ 0x25042044 3 0>,
				<DCC_READ 0x250420b0 1 0>,
				<DCC_READ 0x25042104 1 0>,
				<DCC_READ 0x25042114 1 0>,
				<DCC_READ 0x25048004 5 0>,
				<DCC_READ 0x2504c030 1 0>,
				<DCC_READ 0x25050020 1 0>,
				<DCC_READ 0x2506004c 8 0>,
				<DCC_READ 0x25220348 1 0>,
				<DCC_READ 0x25220480 1 0>,
				<DCC_READ 0x25222400 1 0>,
				<DCC_READ 0x25223220 4 0>,
				<DCC_READ 0x25223308 1 0>,
				<DCC_READ 0x25223318 1 0>,
				<DCC_READ 0x25238100 1 0>,
				<DCC_READ 0x2523c030 1 0>,
				<DCC_READ 0x25242044 3 0>,
				<DCC_READ 0x252420b0 1 0>,
				<DCC_READ 0x25242104 1 0>,
				<DCC_READ 0x25242114 1 0>,
				<DCC_READ 0x25248004 5 0>,
				<DCC_READ 0x2524c030 1 0>,
				<DCC_READ 0x25250020 1 0>,
				<DCC_READ 0x2526004c 8 0>,
				<DCC_READ 0x25420348 1 0>,
				<DCC_READ 0x25420480 1 0>,
				<DCC_READ 0x25422400 1 0>,
				<DCC_READ 0x25423220 4 0>,
				<DCC_READ 0x25423308 1 0>,
				<DCC_READ 0x25423318 1 0>,
				<DCC_READ 0x25438100 1 0>,
				<DCC_READ 0x2543c030 1 0>,
				<DCC_READ 0x25442044 3 0>,
				<DCC_READ 0x254420b0 1 0>,
				<DCC_READ 0x25442104 1 0>,
				<DCC_READ 0x25442114 1 0>,
				<DCC_READ 0x25448004 5 0>,
				<DCC_READ 0x2544c030 1 0>,
				<DCC_READ 0x25450020 1 0>,
				<DCC_READ 0x2546004c 8 0>,
				<DCC_READ 0x25620348 1 0>,
				<DCC_READ 0x25620480 1 0>,
				<DCC_READ 0x25622400 1 0>,
				<DCC_READ 0x25623220 4 0>,
				<DCC_READ 0x25623308 1 0>,
				<DCC_READ 0x25623318 1 0>,
				<DCC_READ 0x25638100 1 0>,
				<DCC_READ 0x2563c030 1 0>,
				<DCC_READ 0x25642044 3 0>,
				<DCC_READ 0x256420b0 1 0>,
				<DCC_READ 0x25642104 1 0>,
				<DCC_READ 0x25642114 1 0>,
				<DCC_READ 0x25648004 5 0>,
				<DCC_READ 0x2564c030 1 0>,
				<DCC_READ 0x25650020 1 0>,
				<DCC_READ 0x2566004c 8 0>,
				<DCC_READ 0x25820348 1 0>,
				<DCC_READ 0x25820480 1 0>,
				<DCC_READ 0x25822400 1 0>,
				<DCC_READ 0x25823220 4 0>,
				<DCC_READ 0x25823308 1 0>,
				<DCC_READ 0x25823318 1 0>,
				<DCC_READ 0x25838100 1 0>,
				<DCC_READ 0x2583c030 1 0>,
				<DCC_READ 0x25842044 3 0>,
				<DCC_READ 0x258420b0 1 0>,
				<DCC_READ 0x25842104 1 0>,
				<DCC_READ 0x25842114 1 0>,
				<DCC_READ 0x25848004 5 0>,
				<DCC_READ 0x2584c030 1 0>,
				<DCC_READ 0x25850020 1 0>,
				<DCC_READ 0x2586004c 8 0>,
				<DCC_READ 0x25a20348 1 0>,
				<DCC_READ 0x25a20480 1 0>,
				<DCC_READ 0x25a22400 1 0>,
				<DCC_READ 0x25a23220 4 0>,
				<DCC_READ 0x25a23308 1 0>,
				<DCC_READ 0x25a23318 1 0>,
				<DCC_READ 0x25a38100 1 0>,
				<DCC_READ 0x25a3c030 1 0>,
				<DCC_READ 0x25a42044 3 0>,
				<DCC_READ 0x25a420b0 1 0>,
				<DCC_READ 0x25a42104 1 0>,
				<DCC_READ 0x25a42114 1 0>,
				<DCC_READ 0x25a48004 5 0>,
				<DCC_READ 0x25a4c030 1 0>,
				<DCC_READ 0x25a50020 1 0>,
				<DCC_READ 0x25a6004c 8 0>,
				<DCC_READ 0x25000004 1 0>,
				<DCC_READ 0x25001004 1 0>,
				<DCC_READ 0x25002004 1 0>,
				<DCC_READ 0x25003004 1 0>,
				<DCC_READ 0x25004004 1 0>,
				<DCC_READ 0x25005004 1 0>,
				<DCC_READ 0x25006004 1 0>,
				<DCC_READ 0x25007004 1 0>,
				<DCC_READ 0x25008004 1 0>,
				<DCC_READ 0x25009004 1 0>,
				<DCC_READ 0x2500a004 1 0>,
				<DCC_READ 0x2500b004 1 0>,
				<DCC_READ 0x2500c004 1 0>,
				<DCC_READ 0x2500d004 1 0>,
				<DCC_READ 0x2500e004 1 0>,
				<DCC_READ 0x2500f004 1 0>,
				<DCC_READ 0x25010004 1 0>,
				<DCC_READ 0x25011004 1 0>,
				<DCC_READ 0x25012004 1 0>,
				<DCC_READ 0x25013004 1 0>,
				<DCC_READ 0x25014004 1 0>,
				<DCC_READ 0x25015004 1 0>,
				<DCC_READ 0x25016004 1 0>,
				<DCC_READ 0x25017004 1 0>,
				<DCC_READ 0x25018004 1 0>,
				<DCC_READ 0x25019004 1 0>,
				<DCC_READ 0x2501a004 1 0>,
				<DCC_READ 0x2501b004 1 0>,
				<DCC_READ 0x2501c004 1 0>,
				<DCC_READ 0x2501d004 1 0>,
				<DCC_READ 0x2501e004 1 0>,
				<DCC_READ 0x2501f004 1 0>,
				<DCC_READ 0x2507601c 4 0>,
				<DCC_READ 0x25076034 4 0>,
				<DCC_READ 0x25076058 1 0>,
				<DCC_READ 0x25076200 1 0>,
				<DCC_READ 0x25077020 1 0>,
				<DCC_READ 0x25077030 20 0>,
				<DCC_READ 0x25077084 1 0>,
				<DCC_READ 0x25077090 5 0>,
				<DCC_READ 0x25077218 8 0>,
				<DCC_READ 0x250a002c 1 0>,
				<DCC_READ 0x250a009c 2 0>,
				<DCC_READ 0x250a00a8 3 0>,
				<DCC_READ 0x250a00b8 1 0>,
				<DCC_READ 0x250a00c0 2 0>,
				<DCC_READ 0x250a00cc 4 0>,
				<DCC_READ 0x250a00e0 1 0>,
				<DCC_READ 0x250a00e8 1 0>,
				<DCC_READ 0x250a00f0 1 0>,
				<DCC_READ 0x250a00f0 1 0>,
				<DCC_READ 0x250a0100 1 0>,
				<DCC_READ 0x250a0108 1 0>,
				<DCC_READ 0x250a0110 1 0>,
				<DCC_READ 0x250a0118 1 0>,
				<DCC_READ 0x250a0120 1 0>,
				<DCC_READ 0x250a0128 1 0>,
				<DCC_READ 0x250a1010 1 0>,
				<DCC_READ 0x250a1070 1 0>,
				<DCC_READ 0x250a3004 1 0>,
				<DCC_READ 0x25200004 1 0>,
				<DCC_READ 0x25201004 1 0>,
				<DCC_READ 0x25202004 1 0>,
				<DCC_READ 0x25203004 1 0>,
				<DCC_READ 0x25204004 1 0>,
				<DCC_READ 0x25205004 1 0>,
				<DCC_READ 0x25206004 1 0>,
				<DCC_READ 0x25207004 1 0>,
				<DCC_READ 0x25208004 1 0>,
				<DCC_READ 0x25209004 1 0>,
				<DCC_READ 0x2520a004 1 0>,
				<DCC_READ 0x2520b004 1 0>,
				<DCC_READ 0x2520c004 1 0>,
				<DCC_READ 0x2520d004 1 0>,
				<DCC_READ 0x2520e004 1 0>,
				<DCC_READ 0x2520f004 1 0>,
				<DCC_READ 0x25210004 1 0>,
				<DCC_READ 0x25211004 1 0>,
				<DCC_READ 0x25212004 1 0>,
				<DCC_READ 0x25213004 1 0>,
				<DCC_READ 0x25214004 1 0>,
				<DCC_READ 0x25215004 1 0>,
				<DCC_READ 0x25216004 1 0>,
				<DCC_READ 0x25217004 1 0>,
				<DCC_READ 0x25218004 1 0>,
				<DCC_READ 0x25219004 1 0>,
				<DCC_READ 0x2521a004 1 0>,
				<DCC_READ 0x2521b004 1 0>,
				<DCC_READ 0x2521c004 1 0>,
				<DCC_READ 0x2521d004 1 0>,
				<DCC_READ 0x2521e004 1 0>,
				<DCC_READ 0x2521f004 1 0>,
				<DCC_READ 0x2527601c 4 0>,
				<DCC_READ 0x25276034 4 0>,
				<DCC_READ 0x25276058 1 0>,
				<DCC_READ 0x25276064 1 0>,
				<DCC_READ 0x25276200 1 0>,
				<DCC_READ 0x25277020 1 0>,
				<DCC_READ 0x25277030 20 0>,
				<DCC_READ 0x25277084 1 0>,
				<DCC_READ 0x25277090 5 0>,
				<DCC_READ 0x25277218 8 0>,
				<DCC_READ 0x252a002c 1 0>,
				<DCC_READ 0x252a009c 2 0>,
				<DCC_READ 0x252a00a8 3 0>,
				<DCC_READ 0x252a00b8 1 0>,
				<DCC_READ 0x252a00c0 2 0>,
				<DCC_READ 0x252a00cc 4 0>,
				<DCC_READ 0x252a00e0 1 0>,
				<DCC_READ 0x252a00e8 1 0>,
				<DCC_READ 0x252a00f0 1 0>,
				<DCC_READ 0x252a00f0 1 0>,
				<DCC_READ 0x252a0100 1 0>,
				<DCC_READ 0x252a0108 1 0>,
				<DCC_READ 0x252a0110 1 0>,
				<DCC_READ 0x252a0118 1 0>,
				<DCC_READ 0x252a0120 1 0>,
				<DCC_READ 0x252a0128 1 0>,
				<DCC_READ 0x252a1010 1 0>,
				<DCC_READ 0x252a1070 1 0>,
				<DCC_READ 0x252a3004 1 0>,
				<DCC_READ 0x25400004 1 0>,
				<DCC_READ 0x25401004 1 0>,
				<DCC_READ 0x25402004 1 0>,
				<DCC_READ 0x25403004 1 0>,
				<DCC_READ 0x25404004 1 0>,
				<DCC_READ 0x25405004 1 0>,
				<DCC_READ 0x25406004 1 0>,
				<DCC_READ 0x25407004 1 0>,
				<DCC_READ 0x25408004 1 0>,
				<DCC_READ 0x25409004 1 0>,
				<DCC_READ 0x2540a004 1 0>,
				<DCC_READ 0x2540b004 1 0>,
				<DCC_READ 0x2540c004 1 0>,
				<DCC_READ 0x2540d004 1 0>,
				<DCC_READ 0x2540e004 1 0>,
				<DCC_READ 0x2540f004 1 0>,
				<DCC_READ 0x25410004 1 0>,
				<DCC_READ 0x25411004 1 0>,
				<DCC_READ 0x25412004 1 0>,
				<DCC_READ 0x25413004 1 0>,
				<DCC_READ 0x25414004 1 0>,
				<DCC_READ 0x25415004 1 0>,
				<DCC_READ 0x25416004 1 0>,
				<DCC_READ 0x25417004 1 0>,
				<DCC_READ 0x25418004 1 0>,
				<DCC_READ 0x25419004 1 0>,
				<DCC_READ 0x2541a004 1 0>,
				<DCC_READ 0x2541b004 1 0>,
				<DCC_READ 0x2541c004 1 0>,
				<DCC_READ 0x2541d004 1 0>,
				<DCC_READ 0x2541e004 1 0>,
				<DCC_READ 0x2541f004 1 0>,
				<DCC_READ 0x2547601c 4 0>,
				<DCC_READ 0x25476034 4 0>,
				<DCC_READ 0x25476058 1 0>,
				<DCC_READ 0x25476064 1 0>,
				<DCC_READ 0x25476200 1 0>,
				<DCC_READ 0x25477020 1 0>,
				<DCC_READ 0x25477030 20 0>,
				<DCC_READ 0x25477084 1 0>,
				<DCC_READ 0x25477090 5 0>,
				<DCC_READ 0x25477218 8 0>,
				<DCC_READ 0x254a002c 1 0>,
				<DCC_READ 0x254a009c 2 0>,
				<DCC_READ 0x254a00a8 3 0>,
				<DCC_READ 0x254a00b8 1 0>,
				<DCC_READ 0x254a00c0 2 0>,
				<DCC_READ 0x254a00cc 4 0>,
				<DCC_READ 0x254a00e0 1 0>,
				<DCC_READ 0x254a00e8 1 0>,
				<DCC_READ 0x254a00f0 1 0>,
				<DCC_READ 0x254a00f0 1 0>,
				<DCC_READ 0x254a0100 1 0>,
				<DCC_READ 0x254a0108 1 0>,
				<DCC_READ 0x254a0110 1 0>,
				<DCC_READ 0x254a0118 1 0>,
				<DCC_READ 0x254a0120 1 0>,
				<DCC_READ 0x254a0128 1 0>,
				<DCC_READ 0x254a1010 1 0>,
				<DCC_READ 0x254a1070 1 0>,
				<DCC_READ 0x254a3004 1 0>,
				<DCC_READ 0x25600004 1 0>,
				<DCC_READ 0x25601004 1 0>,
				<DCC_READ 0x25602004 1 0>,
				<DCC_READ 0x25603004 1 0>,
				<DCC_READ 0x25604004 1 0>,
				<DCC_READ 0x25605004 1 0>,
				<DCC_READ 0x25606004 1 0>,
				<DCC_READ 0x25607004 1 0>,
				<DCC_READ 0x25608004 1 0>,
				<DCC_READ 0x25609004 1 0>,
				<DCC_READ 0x2560a004 1 0>,
				<DCC_READ 0x2560b004 1 0>,
				<DCC_READ 0x2560c004 1 0>,
				<DCC_READ 0x2560d004 1 0>,
				<DCC_READ 0x2560e004 1 0>,
				<DCC_READ 0x2560f004 1 0>,
				<DCC_READ 0x25610004 1 0>,
				<DCC_READ 0x25611004 1 0>,
				<DCC_READ 0x25612004 1 0>,
				<DCC_READ 0x25613004 1 0>,
				<DCC_READ 0x25614004 1 0>,
				<DCC_READ 0x25615004 1 0>,
				<DCC_READ 0x25616004 1 0>,
				<DCC_READ 0x25617004 1 0>,
				<DCC_READ 0x25618004 1 0>,
				<DCC_READ 0x25619004 1 0>,
				<DCC_READ 0x2561a004 1 0>,
				<DCC_READ 0x2561b004 1 0>,
				<DCC_READ 0x2561c004 1 0>,
				<DCC_READ 0x2561d004 1 0>,
				<DCC_READ 0x2561e004 1 0>,
				<DCC_READ 0x2561f004 1 0>,
				<DCC_READ 0x2567601c 4 0>,
				<DCC_READ 0x25676034 4 0>,
				<DCC_READ 0x25676058 1 0>,
				<DCC_READ 0x25676064 1 0>,
				<DCC_READ 0x25676200 1 0>,
				<DCC_READ 0x25677020 1 0>,
				<DCC_READ 0x25677030 20 0>,
				<DCC_READ 0x25677084 1 0>,
				<DCC_READ 0x25677090 5 0>,
				<DCC_READ 0x25677218 8 0>,
				<DCC_READ 0x256a002c 1 0>,
				<DCC_READ 0x256a009c 2 0>,
				<DCC_READ 0x256a00a8 3 0>,
				<DCC_READ 0x256a00b8 1 0>,
				<DCC_READ 0x256a00c0 2 0>,
				<DCC_READ 0x256a00cc 4 0>,
				<DCC_READ 0x256a00e0 1 0>,
				<DCC_READ 0x256a00e8 1 0>,
				<DCC_READ 0x256a00f0 1 0>,
				<DCC_READ 0x256a00f0 1 0>,
				<DCC_READ 0x256a0100 1 0>,
				<DCC_READ 0x256a0108 1 0>,
				<DCC_READ 0x256a0110 1 0>,
				<DCC_READ 0x256a0118 1 0>,
				<DCC_READ 0x256a0120 1 0>,
				<DCC_READ 0x256a0128 1 0>,
				<DCC_READ 0x256a1010 1 0>,
				<DCC_READ 0x256a1070 1 0>,
				<DCC_READ 0x256a3004 1 0>,
				<DCC_READ 0x25a00004 1 0>,
				<DCC_READ 0x25a01004 1 0>,
				<DCC_READ 0x25a02004 1 0>,
				<DCC_READ 0x25a03004 1 0>,
				<DCC_READ 0x25a04004 1 0>,
				<DCC_READ 0x25a05004 1 0>,
				<DCC_READ 0x25a06004 1 0>,
				<DCC_READ 0x25a07004 1 0>,
				<DCC_READ 0x25a08004 1 0>,
				<DCC_READ 0x25a09004 1 0>,
				<DCC_READ 0x25a0a004 1 0>,
				<DCC_READ 0x25a0b004 1 0>,
				<DCC_READ 0x25a0c004 1 0>,
				<DCC_READ 0x25a0d004 1 0>,
				<DCC_READ 0x25a0e004 1 0>,
				<DCC_READ 0x25a0f004 1 0>,
				<DCC_READ 0x25a10004 1 0>,
				<DCC_READ 0x25a11004 1 0>,
				<DCC_READ 0x25a12004 1 0>,
				<DCC_READ 0x25a13004 1 0>,
				<DCC_READ 0x25a14004 1 0>,
				<DCC_READ 0x25a15004 1 0>,
				<DCC_READ 0x25a16004 1 0>,
				<DCC_READ 0x25a17004 1 0>,
				<DCC_READ 0x25a18004 1 0>,
				<DCC_READ 0x25a19004 1 0>,
				<DCC_READ 0x25a1a004 1 0>,
				<DCC_READ 0x25a1b004 1 0>,
				<DCC_READ 0x25a1c004 1 0>,
				<DCC_READ 0x25a1d004 1 0>,
				<DCC_READ 0x25a1e004 1 0>,
				<DCC_READ 0x25a1f004 1 0>,
				<DCC_READ 0x25023210 1 0>,
				<DCC_READ 0x25025000 1 0>,
				<DCC_READ 0x25025010 1 0>,
				<DCC_READ 0x2504002c 4 0>,
				<DCC_READ 0x25040048 5 0>,
				<DCC_READ 0x25040060 2 0>,
				<DCC_READ 0x25040070 5 0>,
				<DCC_READ 0x2507718c 1 0>,
				<DCC_READ 0x250771b0 1 0>,
				<DCC_READ 0x25077204 5 0>,
				<DCC_READ 0x250a6008 3 0>,
				<DCC_READ 0x250a7008 3 0>,
				<DCC_READ 0x25223210 1 0>,
				<DCC_READ 0x25225000 1 0>,
				<DCC_READ 0x25225010 1 0>,
				<DCC_READ 0x2524002c 4 0>,
				<DCC_READ 0x25240048 5 0>,
				<DCC_READ 0x25240060 2 0>,
				<DCC_READ 0x25240070 5 0>,
				<DCC_READ 0x2527718c 1 0>,
				<DCC_READ 0x252771b0 1 0>,
				<DCC_READ 0x25277204 5 0>,
				<DCC_READ 0x252a6008 3 0>,
				<DCC_READ 0x252a7008 3 0>,
				<DCC_READ 0x25423210 1 0>,
				<DCC_READ 0x25425000 1 0>,
				<DCC_READ 0x25425010 1 0>,
				<DCC_READ 0x2544002c 4 0>,
				<DCC_READ 0x25440048 5 0>,
				<DCC_READ 0x25440060 2 0>,
				<DCC_READ 0x25440070 5 0>,
				<DCC_READ 0x2547718c 1 0>,
				<DCC_READ 0x254771b0 1 0>,
				<DCC_READ 0x25477204 5 0>,
				<DCC_READ 0x254a6008 3 0>,
				<DCC_READ 0x254a7008 3 0>,
				<DCC_READ 0x25623210 1 0>,
				<DCC_READ 0x25625000 1 0>,
				<DCC_READ 0x25625010 1 0>,
				<DCC_READ 0x2564002c 4 0>,
				<DCC_READ 0x25640048 5 0>,
				<DCC_READ 0x25640060 2 0>,
				<DCC_READ 0x25640070 5 0>,
				<DCC_READ 0x2567718c 1 0>,
				<DCC_READ 0x256771b0 1 0>,
				<DCC_READ 0x25677204 5 0>,
				<DCC_READ 0x256a6008 3 0>,
				<DCC_READ 0x256a7008 3 0>,
				<DCC_READ 0x250a9004 1 0>,
				<DCC_READ 0x250a9010 3 0>,
				<DCC_READ 0x250a9020 3 0>,
				<DCC_READ 0x250a9030 3 0>,
				<DCC_READ 0x250a9040 3 0>,
				<DCC_READ 0x250a9050 3 0>,
				<DCC_READ 0x250aa004 1 0>,
				<DCC_READ 0x250aa010 3 0>,
				<DCC_READ 0x250aa020 3 0>,
				<DCC_READ 0x250aa030 3 0>,
				<DCC_READ 0x250aa040 3 0>,
				<DCC_READ 0x250aa050 3 0>,
				<DCC_READ 0x250b001c 1 0>,
				<DCC_READ 0x250b101c 1 0>,
				<DCC_READ 0x250b201c 1 0>,
				<DCC_READ 0x250b301c 1 0>,
				<DCC_READ 0x250b401c 1 0>,
				<DCC_READ 0x250b501c 1 0>,
				<DCC_READ 0x250b601c 1 0>,
				<DCC_READ 0x250b701c 1 0>,
				<DCC_READ 0x250b801c 1 0>,
				<DCC_READ 0x250b901c 1 0>,
				<DCC_READ 0x250ba01c 1 0>,
				<DCC_READ 0x250bb01c 1 0>,
				<DCC_READ 0x250bc01c 1 0>,
				<DCC_READ 0x250bd01c 1 0>,
				<DCC_READ 0x250be01c 1 0>,
				<DCC_READ 0x250bf01c 1 0>,
				<DCC_READ 0x252a9004 1 0>,
				<DCC_READ 0x252a9010 3 0>,
				<DCC_READ 0x252a9020 3 0>,
				<DCC_READ 0x252a9030 3 0>,
				<DCC_READ 0x252a9040 3 0>,
				<DCC_READ 0x252a9050 3 0>,
				<DCC_READ 0x252aa004 1 0>,
				<DCC_READ 0x252aa010 3 0>,
				<DCC_READ 0x252aa020 3 0>,
				<DCC_READ 0x252aa030 3 0>,
				<DCC_READ 0x252aa040 3 0>,
				<DCC_READ 0x252aa050 3 0>,
				<DCC_READ 0x252b001c 1 0>,
				<DCC_READ 0x252b101c 1 0>,
				<DCC_READ 0x252b201c 1 0>,
				<DCC_READ 0x252b301c 1 0>,
				<DCC_READ 0x252b401c 1 0>,
				<DCC_READ 0x252b501c 1 0>,
				<DCC_READ 0x252b601c 1 0>,
				<DCC_READ 0x252b701c 1 0>,
				<DCC_READ 0x252b801c 1 0>,
				<DCC_READ 0x252b901c 1 0>,
				<DCC_READ 0x252ba01c 1 0>,
				<DCC_READ 0x252bb01c 1 0>,
				<DCC_READ 0x252bc01c 1 0>,
				<DCC_READ 0x252bd01c 1 0>,
				<DCC_READ 0x252be01c 1 0>,
				<DCC_READ 0x252bf01c 1 0>,
				<DCC_READ 0x254a9004 1 0>,
				<DCC_READ 0x254a9010 3 0>,
				<DCC_READ 0x254a9020 3 0>,
				<DCC_READ 0x254a9030 3 0>,
				<DCC_READ 0x254a9040 3 0>,
				<DCC_READ 0x254a9050 3 0>,
				<DCC_READ 0x254aa004 1 0>,
				<DCC_READ 0x254aa010 3 0>,
				<DCC_READ 0x254aa020 3 0>,
				<DCC_READ 0x254aa030 3 0>,
				<DCC_READ 0x254aa040 3 0>,
				<DCC_READ 0x254aa050 3 0>,
				<DCC_READ 0x254b001c 1 0>,
				<DCC_READ 0x254b101c 1 0>,
				<DCC_READ 0x254b201c 1 0>,
				<DCC_READ 0x254b301c 1 0>,
				<DCC_READ 0x254b401c 1 0>,
				<DCC_READ 0x254b501c 1 0>,
				<DCC_READ 0x254b601c 1 0>,
				<DCC_READ 0x254b701c 1 0>,
				<DCC_READ 0x254b801c 1 0>,
				<DCC_READ 0x254b901c 1 0>,
				<DCC_READ 0x254ba01c 1 0>,
				<DCC_READ 0x254bb01c 1 0>,
				<DCC_READ 0x254bc01c 1 0>,
				<DCC_READ 0x254bd01c 1 0>,
				<DCC_READ 0x254be01c 1 0>,
				<DCC_READ 0x254bf01c 1 0>,
				<DCC_READ 0x256a9004 1 0>,
				<DCC_READ 0x256a9010 3 0>,
				<DCC_READ 0x256a9020 3 0>,
				<DCC_READ 0x256a9030 3 0>,
				<DCC_READ 0x256a9040 3 0>,
				<DCC_READ 0x256a9050 3 0>,
				<DCC_READ 0x256aa004 1 0>,
				<DCC_READ 0x256aa010 3 0>,
				<DCC_READ 0x256aa020 3 0>,
				<DCC_READ 0x256aa030 3 0>,
				<DCC_READ 0x256aa040 3 0>,
				<DCC_READ 0x256aa050 3 0>,
				<DCC_READ 0x256b001c 1 0>,
				<DCC_READ 0x256b101c 1 0>,
				<DCC_READ 0x256b201c 1 0>,
				<DCC_READ 0x256b301c 1 0>,
				<DCC_READ 0x256b401c 1 0>,
				<DCC_READ 0x256b501c 1 0>,
				<DCC_READ 0x256b601c 1 0>,
				<DCC_READ 0x256b701c 1 0>,
				<DCC_READ 0x256b801c 1 0>,
				<DCC_READ 0x256b901c 1 0>,
				<DCC_READ 0x256ba01c 1 0>,
				<DCC_READ 0x256bb01c 1 0>,
				<DCC_READ 0x256bc01c 1 0>,
				<DCC_READ 0x256bd01c 1 0>,
				<DCC_READ 0x256be01c 1 0>,
				<DCC_READ 0x256bf01c 1 0>,
				<DCC_READ 0x258a4040 48 0>,
				<DCC_READ 0x258b0000 1 0>,
				<DCC_READ 0x258b005c 1 0>,
				<DCC_READ 0x258b1000 1 0>,
				<DCC_READ 0x258b105c 1 0>,
				<DCC_READ 0x258b2000 1 0>,
				<DCC_READ 0x258b205c 1 0>,
				<DCC_READ 0x258b3000 1 0>,
				<DCC_READ 0x258b305c 1 0>,
				<DCC_READ 0x258b4000 1 0>,
				<DCC_READ 0x258b405c 1 0>,
				<DCC_READ 0x258b5000 1 0>,
				<DCC_READ 0x258b505c 1 0>,
				<DCC_READ 0x258b6000 1 0>,
				<DCC_READ 0x258b605c 1 0>,
				<DCC_READ 0x258b7000 1 0>,
				<DCC_READ 0x258b705c 1 0>,
				<DCC_READ 0x258b8000 1 0>,
				<DCC_READ 0x258b805c 1 0>,
				<DCC_READ 0x258b9000 1 0>,
				<DCC_READ 0x258b905c 1 0>,
				<DCC_READ 0x258ba000 1 0>,
				<DCC_READ 0x258ba05c 1 0>,
				<DCC_READ 0x258bb000 1 0>,
				<DCC_READ 0x258bb05c 1 0>,
				<DCC_READ 0x258bc000 1 0>,
				<DCC_READ 0x258bc05c 1 0>,
				<DCC_READ 0x258bd000 1 0>,
				<DCC_READ 0x258bd05c 1 0>,
				<DCC_READ 0x258be000 1 0>,
				<DCC_READ 0x258be05c 1 0>,
				<DCC_READ 0x258bf000 1 0>,
				<DCC_READ 0x258bf05c 1 0>,
				<DCC_READ 0x24405688 2 0>,
				<DCC_READ 0x24605688 2 0>,
				<DCC_READ 0x24485688 2 0>,
				<DCC_READ 0x24685688 2 0>,
				<DCC_READ 0x24407010 3 0>,
				<DCC_READ 0x24607010 3 0>,
				<DCC_READ 0x24487010 3 0>,
				<DCC_READ 0x24687010 3 0>,
				<DCC_READ 0x32302028 1 0>,
				<DCC_READ 0x320a4404 2 0>,
				<DCC_READ 0x323c0404 2 0>,
				<DCC_READ 0x129000 1 0>,
				<DCC_READ 0x12903c 1 0>,
				<DCC_READ 0x171004 1 0>,
				<DCC_READ 0x17100c 6 0>,
				<DCC_READ 0x17115c 1 0>,
				<DCC_READ 0x17b000 1 0>,
				<DCC_READ 0x17b03c 1 0>,
				<DCC_READ 0x17c000 1 0>,
				<DCC_READ 0x17c03c 1 0>,
				<DCC_READ 0x17d000 1 0>,
				<DCC_READ 0x17d03c 1 0>,
				<DCC_READ 0x17e000 1 0>,
				<DCC_READ 0x17e03c 1 0>,
				<DCC_READ 0x3d00000 1 0>,
				<DCC_READ 0x3d00008 1 0>,
				<DCC_READ 0x3d00044 1 0>,
				<DCC_READ 0x3d00058 6 0>,
				<DCC_READ 0x3d0007c 20 0>,
				<DCC_READ 0x3d000e0 5 0>,
				<DCC_READ 0x3d00108 1 0>,
				<DCC_READ 0x3d00110 1 0>,
				<DCC_READ 0x3d0011c 1 0>,
				<DCC_READ 0x3d00124 2 0>,
				<DCC_READ 0x3d00130 1 0>,
				<DCC_READ 0x3d00140 1 0>,
				<DCC_READ 0x3d00158 1 0>,
				<DCC_READ 0x3d002b4 2 0>,
				<DCC_READ 0x3d002c0 1 0>,
				<DCC_READ 0x3d002d0 1 0>,
				<DCC_READ 0x3d002e0 1 0>,
				<DCC_READ 0x3d002f0 1 0>,
				<DCC_READ 0x3d00300 1 0>,
				<DCC_READ 0x3d00310 1 0>,
				<DCC_READ 0x3d00320 1 0>,
				<DCC_READ 0x3d00330 1 0>,
				<DCC_READ 0x3d00340 1 0>,
				<DCC_READ 0x3d00350 1 0>,
				<DCC_READ 0x3d00360 1 0>,
				<DCC_READ 0x3d00370 1 0>,
				<DCC_READ 0x3d00380 1 0>,
				<DCC_READ 0x3d00390 1 0>,
				<DCC_READ 0x3d003a0 1 0>,
				<DCC_READ 0x3d003b0 1 0>,
				<DCC_READ 0x3d003c0 1 0>,
				<DCC_READ 0x3d003d0 1 0>,
				<DCC_READ 0x3d003e0 1 0>,
				<DCC_READ 0x3d00400 1 0>,
				<DCC_READ 0x3d00410 8 0>,
				<DCC_READ 0x3d0043c 15 0>,
				<DCC_READ 0x3d004bc 1 0>,
				<DCC_READ 0x3d00800 14 0>,
				<DCC_READ 0x3d00840 4 0>,
				<DCC_READ 0x3d00854 41 0>,
				<DCC_READ 0x3d00980 9 0>,
				<DCC_READ 0x3d009c8 3 0>,
				<DCC_READ 0x3d00a04 13 0>,
				<DCC_READ 0x3d01444 1 0>,
				<DCC_READ 0x3d014d4 2 0>,
				<DCC_READ 0x3d0201c 1 0>,
				<DCC_READ 0x3d0f000 1 0>,
				<DCC_READ 0x3d0f114 3 0>,
				<DCC_READ 0x3d3b000 2 0>,
				<DCC_READ 0x3d3b014 1 0>,
				<DCC_READ 0x3d3b01c 1 0>,
				<DCC_READ 0x3d3b028 1 0>,
				<DCC_READ 0x3d3b0ac 1 0>,
				<DCC_READ 0x3d3b100 2 0>,
				<DCC_READ 0x3d3b114 1 0>,
				<DCC_READ 0x3d3b11c 1 0>,
				<DCC_READ 0x3d3b128 1 0>,
				<DCC_READ 0x3d3b1ac 1 0>,
				<DCC_READ 0x3d50000 21 0>,
				<DCC_READ 0x3d500d0 1 0>,
				<DCC_READ 0x3d500d8 1 0>,
				<DCC_READ 0x3d50100 3 0>,
				<DCC_READ 0x3d50200 5 0>,
				<DCC_READ 0x3d50400 3 0>,
				<DCC_READ 0x3d50450 1 0>,
				<DCC_READ 0x3d50460 2 0>,
				<DCC_READ 0x3d50490 12 0>,
				<DCC_READ 0x3d50550 1 0>,
				<DCC_READ 0x3d50d00 2 0>,
				<DCC_READ 0x3d50d10 1 0>,
				<DCC_READ 0x3d50d18 6 0>,
				<DCC_READ 0x3d50d34 5 0>,
				<DCC_READ 0x3d7d000 12 0>,
				<DCC_READ 0x3d7d03c 3 0>,
				<DCC_READ 0x3d7d400 1 0>,
				<DCC_READ 0x3d7d41c 1 0>,
				<DCC_READ 0x3d7d424 3 0>,
				<DCC_READ 0x3d7e000 5 0>,
				<DCC_READ 0x3d7e01c 2 0>,
				<DCC_READ 0x3d7e02c 2 0>,
				<DCC_READ 0x3d7e03c 1 0>,
				<DCC_READ 0x3d7e044 1 0>,
				<DCC_READ 0x3d7e04c 5 0>,
				<DCC_READ 0x3d7e064 4 0>,
				<DCC_READ 0x3d7e090 7 0>,
				<DCC_READ 0x3d7e0b4 4 0>,
				<DCC_READ 0x3d7e100 20 0>,
				<DCC_READ 0x3d7e180 1 0>,
				<DCC_READ 0x3d7e1c0 10 0>,
				<DCC_READ 0x3d7e1fc 1 0>,
				<DCC_READ 0x3d7e220 2 0>,
				<DCC_READ 0x3d7e300 2 0>,
				<DCC_READ 0x3d7e30c 2 0>,
				<DCC_READ 0x3d7e340 1 0>,
				<DCC_READ 0x3d7e3b0 1 0>,
				<DCC_READ 0x3d7e3c0 2 0>,
				<DCC_READ 0x3d7e440 4 0>,
				<DCC_READ 0x3d7e480 2 0>,
				<DCC_READ 0x3d7e490 2 0>,
				<DCC_READ 0x3d7e4a0 2 0>,
				<DCC_READ 0x3d7e4b0 2 0>,
				<DCC_READ 0x3d7e500 1 0>,
				<DCC_READ 0x3d7e508 3 0>,
				<DCC_READ 0x3d7e520 3 0>,
				<DCC_READ 0x3d7e544 1 0>,
				<DCC_READ 0x3d7e574 1 0>,
				<DCC_READ 0x3d7e588 1 0>,
				<DCC_READ 0x3d7e5cc 1 0>,
				<DCC_READ 0x3d7e600 2 0>,
				<DCC_READ 0x3d7e610 3 0>,
				<DCC_READ 0x3d7e648 2 0>,
				<DCC_READ 0x3d7e658 9 0>,
				<DCC_READ 0x3d7e700 1 0>,
				<DCC_READ 0x3d7e714 16 0>,
				<DCC_READ 0x3d7e7c0 2 0>,
				<DCC_READ 0x3d7e7e0 3 0>,
				<DCC_READ 0x3d8e100 2 0>,
				<DCC_READ 0x3d8ec00 2 0>,
				<DCC_READ 0x3d8ec0c 1 0>,
				<DCC_READ 0x3d8ec14 10 0>,
				<DCC_READ 0x3d8ec40 4 0>,
				<DCC_READ 0x3d8ec54 2 0>,
				<DCC_READ 0x3d8eca0 1 0>,
				<DCC_READ 0x3d8ecc0 1 0>,
				<DCC_READ 0x3d90000 14 0>,
				<DCC_READ 0x3d9003c 1 0>,
				<DCC_READ 0x3d91000 14 0>,
				<DCC_READ 0x3d9103c 1 0>,
				<DCC_READ 0x3d94000 2 0>,
				<DCC_READ 0x3d95000 4 0>,
				<DCC_READ 0x3d96000 4 0>,
				<DCC_READ 0x3d97000 4 0>,
				<DCC_READ 0x3d98000 4 0>,
				<DCC_READ 0x3d99000 6 0>,
				<DCC_READ 0x3d99028 10 0>,
				<DCC_READ 0x3d99060 2 0>,
				<DCC_READ 0x3d9906c 6 0>,
				<DCC_READ 0x3d99088 6 0>,
				<DCC_READ 0x3d990c8 9 0>,
				<DCC_READ 0x3d990f0 5 0>,
				<DCC_READ 0x3d9910c 6 0>,
				<DCC_READ 0x3d99134 2 0>,
				<DCC_READ 0x3d99144 2 0>,
				<DCC_READ 0x3d99150 4 0>,
				<DCC_READ 0x3d99164 3 0>,
				<DCC_READ 0x3d99180 9 0>,
				<DCC_READ 0x3d991b4 3 0>,
				<DCC_READ 0x3d99500 4 0>,
				<DCC_READ 0x3d99528 5 0>,
				<DCC_READ 0x3d99550 29 0>,
				<DCC_READ 0x3d99800 8 0>,
				<DCC_READ 0x3d99828 1 0>,
				<DCC_READ 0x3d9983c 1 0>,
				<DCC_READ 0x3d998ac 1 0>,
				<DCC_READ 0x3d9e000 1 0>,
				<DCC_READ 0x3d9e040 5 0>,
				<DCC_READ 0x3d9e080 5 0>,
				<DCC_READ 0x3d9e0cc 9 0>,
				<DCC_READ 0x3d9e0fc 2 0>,
				<DCC_READ 0x3d9e118 2 0>,
				<DCC_READ 0x3d9e134 1 0>,
				<DCC_READ 0x17421000 2 0>;
		};

		link_list_1 {
			qcom,curr-link-list = <4>;
			qcom,data-sink = "sram";
			qcom,ap-qad-override;
			qcom,link-list = <DCC_READ 0x17421000 2 0>,
				<DCC_READ 0x6800000 1 0>,
				<DCC_READ 0x6802028 1 0>,
				<DCC_READ 0x68c0404 2 0>,
				<DCC_READ 0x7200404 2 0>,
				<DCC_READ 0x6e26000 1 0>,
				<DCC_READ 0x6e26024 1 0>,
				<DCC_READ 0x6e2608c 1 0>,
				<DCC_READ 0x6e260ac 6 0>,
				<DCC_READ 0x6e26100 5 0>,
				<DCC_READ 0x6e26120 4 0>,
				<DCC_READ 0x6e261ac 1 0>,
				<DCC_READ 0x6e26504 1 0>,
				<DCC_READ 0x01400008 1 0>,
				<DCC_READ 0x01400010 1 0>,
				<DCC_READ 0x01400020 8 0>,
				<DCC_READ 0x0145be40 1 0>,
				<DCC_READ 0x0145be48 1 0>,
				<DCC_READ 0x142a010 1 0>,
				<DCC_READ 0x142b010 1 0>,
				<DCC_READ 0x142c010 1 0>,
				<DCC_READ 0x1430010 1 0>,
				<DCC_READ 0x1432010 1 0>,
				<DCC_READ 0x1433010 1 0>,
				<DCC_READ 0x1435010 1 0>,
				<DCC_READ 0x0145b808 1 0>,
				<DCC_READ 0x0145b818 1 0>,
				<DCC_LOOP 0x6 0 0>,
				<DCC_READ 0x0145b810 2 0>,
				<DCC_LOOP 0x1 0 0>,
				<DCC_READ 0x1403008 1 0>,
				<DCC_READ 0x1403018 1 0>,
				<DCC_LOOP 0x6 0 0>,
				<DCC_READ 0x1403010 2 0>,
				<DCC_LOOP 0x1 0 0>,
				<DCC_READ 0x01480008 1 0>,
				<DCC_READ 0x01480010 1 0>,
				<DCC_READ 0x01480020 8 0>,
				<DCC_READ 0x014dbe40 1 0>,
				<DCC_READ 0x014dbe48 1 0>,
				<DCC_READ 0x14a8010 1 0>,
				<DCC_READ 0x14a9010 1 0>,
				<DCC_READ 0x14ad010 1 0>,
				<DCC_READ 0x14ae010 1 0>,
				<DCC_READ 0x01482008 1 0>,
				<DCC_READ 0x01482018 1 0>,
				<DCC_LOOP 0x5 0 0>,
				<DCC_READ 0x01482010 2 0>,
				<DCC_LOOP 0x1 0 0>,
				<DCC_READ 0x1483008 1 0>,
				<DCC_READ 0x1483018 1 0>,
				<DCC_LOOP 0xb 0 0>,
				<DCC_READ 0x1483010 2 0>,
				<DCC_LOOP 0x1 0 0>,
				<DCC_READ 0x01680010 1 0>,
				<DCC_READ 0x01680020 8 0>,
				<DCC_READ 0x01681040 1 0>,
				<DCC_READ 0x01681048 1 0>,
				<DCC_READ 0x1690010 1 0>,
				<DCC_READ 0x1698010 1 0>,
				<DCC_READ 0x1699010 1 0>,
				<DCC_READ 0x169c010 1 0>,
				<DCC_READ 0x169d010 1 0>,
				<DCC_READ 0x01682018 1 0>,
				<DCC_READ 0x01682008 1 0>,
				<DCC_LOOP 0x5 0 0>,
				<DCC_READ 0x01682010 2 0>,
				<DCC_LOOP 0x1 0 0>,
				<DCC_READ 0x016e0008 1 0>,
				<DCC_READ 0x016e0010 1 0>,
				<DCC_READ 0x016e0020 8 0>,
				<DCC_READ 0x016e0240 1 0>,
				<DCC_READ 0x016e0248 1 0>,
				<DCC_READ 0x16ec010 1 0>,
				<DCC_READ 0x16ed010 1 0>,
				<DCC_READ 0x16ef210 1 0>,
				<DCC_READ 0x16f0010 1 0>,
				<DCC_READ 0x16f9010 1 0>,
				<DCC_READ 0x016e1018 1 0>,
				<DCC_READ 0x016e1008 1 0>,
				<DCC_LOOP 0x2 0 0>,
				<DCC_READ 0x016e1010 2 0>,
				<DCC_LOOP 0x1 0 0>,
				<DCC_READ 0x016e1088 1 0>,
				<DCC_READ 0x016e1098 1 0>,
				<DCC_LOOP 0x2 0 0>,
				<DCC_READ 0x16e1090 2 0>,
				<DCC_LOOP 0x1 0 0>,
				<DCC_READ 0x016e1118 1 0>,
				<DCC_READ 0x016e1108 1 0>,
				<DCC_LOOP 0x6 0 0>,
				<DCC_READ 0x016e1110 2 0>,
				<DCC_LOOP 0x1 0 0>,
				<DCC_READ 0x016e1208 1 0>,
				<DCC_READ 0x016e1218 1 0>,
				<DCC_LOOP 0x2 0 0>,
				<DCC_READ 0x016e1210 2 0>,
				<DCC_LOOP 0x1 0 0>,
				<DCC_READ 0x01700008 1 0>,
				<DCC_READ 0x01700010 1 0>,
				<DCC_READ 0x01700020 8 0>,
				<DCC_READ 0x01700248 1 0>,
				<DCC_READ 0x1712010 1 0>,
				<DCC_READ 0x1713010 1 0>,
				<DCC_READ 0x1715010 1 0>,
				<DCC_READ 0x1716010 1 0>,
				<DCC_READ 0x1717010 1 0>,
				<DCC_READ 0x1718010 1 0>,
				<DCC_READ 0x01701018 1 0>,
				<DCC_READ 0x01701008 1 0>,
				<DCC_LOOP 0x4 0 0>,
				<DCC_READ 0x01701010 2 0>,
				<DCC_LOOP 0x1 0 0>,
				<DCC_READ 0x01701098 1 0>,
				<DCC_READ 0x01701088 1 0>,
				<DCC_READ 0x01701090 2 0>,
				<DCC_READ 0x01701288 1 0>,
				<DCC_READ 0x01701298 1 0>,
				<DCC_READ 0x01701290 2 0>,
				<DCC_READ 0x16c0008 1 0>,
				<DCC_READ 0x16c0010 1 0>,
				<DCC_READ 0x16c0020 8 0>,
				<DCC_READ 0x16c0240 1 0>,
				<DCC_READ 0x16c0248 1 0>,
				<DCC_READ 0x16cb010 1 0>,
				<DCC_READ 0x16c2008 1 0>,
				<DCC_READ 0x16c2018 1 0>,
				<DCC_LOOP 0x3 0 0>,
				<DCC_READ 0x016c2010 2 0>,
				<DCC_LOOP 0x1 0 0>,
				<DCC_READ 0x16c3008 1 0>,
				<DCC_READ 0x16c3018 1 0>,
				<DCC_LOOP 0x3 0 0>,
				<DCC_READ 0x016c3010 2 0>,
				<DCC_LOOP 0x1 0 0>,
				<DCC_READ 0x01600008 1 0>,
				<DCC_READ 0x01600010 1 0>,
				<DCC_READ 0x01600020 8 0>,
				<DCC_READ 0x1600240 5 0>,
				<DCC_READ 0x1600258 1 0>,
				<DCC_READ 0x01602018 1 0>,
				<DCC_READ 0x01602008 1 0>,
				<DCC_LOOP 0x7 0 0>,
				<DCC_READ 0x01602010 2 0>,
				<DCC_LOOP 0x1 0 0>,
				<DCC_READ 0x01602108 1 0>,
				<DCC_READ 0x01602118 1 0>,
				<DCC_LOOP 0x2 0 0>,
				<DCC_READ 0x01602110 2 0>,
				<DCC_LOOP 0x1 0 0>,
				<DCC_READ 0x01602188 1 0>,
				<DCC_READ 0x01602198 1 0>,
				<DCC_LOOP 0x2 0 0>,
				<DCC_READ 0x01602190 2 0>,
				<DCC_LOOP 0x1 0 0>,
				<DCC_READ 0x01602208 1 0>,
				<DCC_READ 0x01602218 1 0>,
				<DCC_LOOP 0x2 0 0>,
				<DCC_READ 0x01602210 2 0>,
				<DCC_LOOP 0x1 0 0>,
				<DCC_READ 0x01602288 1 0>,
				<DCC_READ 0x01602298 1 0>,
				<DCC_LOOP 0x2 0 0>,
				<DCC_READ 0x01602290 2 0>,
				<DCC_LOOP 0x1 0 0>,
				<DCC_READ 0x01602308 1 0>,
				<DCC_READ 0x01602318 1 0>,
				<DCC_LOOP 0x2 0 0>,
				<DCC_READ 0x01602310 2 0>,
				<DCC_LOOP 0x1 0 0>,
				<DCC_READ 0x01602388 1 0>,
				<DCC_READ 0x01602398 1 0>,
				<DCC_LOOP 0x2 0 0>,
				<DCC_READ 0x01602390 2 0>,
				<DCC_LOOP 0x1 0 0>,
				<DCC_READ 0x01500008 1 0>,
				<DCC_READ 0x01500010 1 0>,
				<DCC_READ 0x01500020 8 0>,
				<DCC_READ 0x01500240 1 0>,
				<DCC_READ 0x01500248 1 0>,
				<DCC_READ 0x01500440 1 0>,
				<DCC_READ 0x01500448 1 0>,
				<DCC_READ 0x01502018 1 0>,
				<DCC_READ 0x01502008 1 0>,
				<DCC_LOOP 0x8 0 0>,
				<DCC_READ 0x01502010 2 0>,
				<DCC_LOOP 0x1 0 0>,
				<DCC_READ 0x01502098 1 0>,
				<DCC_READ 0x01502088 1 0>,
				<DCC_LOOP 0x2 0 0>,
				<DCC_READ 0x01502090 2 0>,
				<DCC_LOOP 0x1 0 0>,
				<DCC_READ 0x01502508 1 0>,
				<DCC_READ 0x01502518 1 0>,
				<DCC_LOOP 0x2 0 0>,
				<DCC_READ 0x01502510 2 0>,
				<DCC_LOOP 0x1 0 0>,
				<DCC_READ 0x17610008 1 0>,
				<DCC_READ 0x17610010 1 0>,
				<DCC_READ 0x17610020 8 0>,
				<DCC_READ 0x17610240 1 0>,
				<DCC_READ 0x17610248 1 0>,
				<DCC_READ 0x17612018 1 0>,
				<DCC_READ 0x17612008 1 0>,
				<DCC_LOOP 0x5 0 0>,
				<DCC_READ 0x17612010 2 0>,
				<DCC_LOOP 0x1 0 0>,
				<DCC_READ 0x320c0008 1 0>,
				<DCC_READ 0x320c0010 1 0>,
				<DCC_READ 0x320c0020 8 0>,
				<DCC_READ 0x320c1018 1 0>,
				<DCC_READ 0x320c1008 1 0>,
				<DCC_LOOP 0x4 0 0>,
				<DCC_READ 0x320c1010 2 0>,
				<DCC_LOOP 0x1 0 0>,
				<DCC_READ 0x17100104 29 0>,
				<DCC_READ 0x17100204 29 0>,
				<DCC_READ 0x17100384 29 0>,
				<DCC_READ 0x178b0250 3 0>,
				<DCC_READ 0xb281024 1 0>,
				<DCC_READ 0xbde1034 1 0>,
				<DCC_READ 0xb201020 2 0>,
				<DCC_READ 0xb211020 2 0>,
				<DCC_READ 0xb221020 2 0>,
				<DCC_READ 0xb231020 2 0>,
				<DCC_READ 0xb204520 1 0>,
				<DCC_READ 0xb200000 1 0>,
				<DCC_READ 0xb210000 1 0>,
				<DCC_READ 0xb220000 1 0>,
				<DCC_READ 0xb230000 1 0>,
				<DCC_READ 0x17a00010 1 0>,
				<DCC_READ 0x17a10010 1 0>,
				<DCC_READ 0x17a20010 1 0>,
				<DCC_READ 0x17a30010 1 0>,
				<DCC_READ 0x17a00030 1 0>,
				<DCC_READ 0x17a10030 1 0>,
				<DCC_READ 0x17a20030 1 0>,
				<DCC_READ 0x17a30030 1 0>,
				<DCC_READ 0x17a00038 1 0>,
				<DCC_READ 0x17a10038 1 0>,
				<DCC_READ 0x17a20038 1 0>,
				<DCC_READ 0x17a30038 1 0>,
				<DCC_READ 0x17a00040 1 0>,
				<DCC_READ 0x17a10040 1 0>,
				<DCC_READ 0x17a20040 1 0>,
				<DCC_READ 0x17a30040 1 0>,
				<DCC_READ 0x17a00048 1 0>,
				<DCC_READ 0x17a00400 3 0>,
				<DCC_READ 0x17a10400 3 0>,
				<DCC_READ 0x17a20400 3 0>,
				<DCC_READ 0x17a30400 3 0>,
				<DCC_READ 0x17a10d3c 1 0>,
				<DCC_READ 0x17a10d54 1 0>,
				<DCC_READ 0x17a10d6c 1 0>,
				<DCC_READ 0x17a10d84 1 0>,
				<DCC_READ 0x17a10d9c 1 0>,
				<DCC_READ 0x17a10db4 1 0>,
				<DCC_READ 0x17a10dcc 1 0>,
				<DCC_READ 0x17a10de4 1 0>,
				<DCC_READ 0x17a10dfc 1 0>,
				<DCC_READ 0x17a10e14 1 0>,
				<DCC_READ 0x17a10e2c 1 0>,
				<DCC_READ 0x17a10e44 1 0>,
				<DCC_READ 0x17a10e5c 1 0>,
				<DCC_READ 0x17a10e74 1 0>,
				<DCC_READ 0x17a10e8c 1 0>,
				<DCC_READ 0x17a10ea4 1 0>,
				<DCC_READ 0x17a10fdc 1 0>,
				<DCC_READ 0x17a10ff4 1 0>,
				<DCC_READ 0x17a1100c 1 0>,
				<DCC_READ 0x17a11024 1 0>,
				<DCC_READ 0x17a1103c 1 0>,
				<DCC_READ 0x17a11054 1 0>,
				<DCC_READ 0x17a1106c 1 0>,
				<DCC_READ 0x17a11084 1 0>,
				<DCC_READ 0x17a1109c 1 0>,
				<DCC_READ 0x17a110b4 1 0>,
				<DCC_READ 0x17a110cc 1 0>,
				<DCC_READ 0x17a110e4 1 0>,
				<DCC_READ 0x17a110fc 1 0>,
				<DCC_READ 0x17a11114 1 0>,
				<DCC_READ 0x17a1112c 1 0>,
				<DCC_READ 0x17a11144 1 0>,
				<DCC_READ 0x17a1127c 1 0>,
				<DCC_READ 0x17a11294 1 0>,
				<DCC_READ 0x17a112ac 1 0>,
				<DCC_READ 0x17a112c4 1 0>,
				<DCC_READ 0x17a112dc 1 0>,
				<DCC_READ 0x17a112f4 1 0>,
				<DCC_READ 0x17a1130c 1 0>,
				<DCC_READ 0x17a11324 1 0>,
				<DCC_READ 0x17a1133c 1 0>,
				<DCC_READ 0x17a11354 1 0>,
				<DCC_READ 0x17a1136c 1 0>,
				<DCC_READ 0x17a11384 1 0>,
				<DCC_READ 0x17a1139c 1 0>,
				<DCC_READ 0x17a113b4 1 0>,
				<DCC_READ 0x17a113cc 1 0>,
				<DCC_READ 0x17a113e4 1 0>,
				<DCC_READ 0x17a1151c 1 0>,
				<DCC_READ 0x17a11534 1 0>,
				<DCC_READ 0x17a1154c 1 0>,
				<DCC_READ 0x17a11564 1 0>,
				<DCC_READ 0x17a1157c 1 0>,
				<DCC_READ 0x17a11594 1 0>,
				<DCC_READ 0x17a115ac 1 0>,
				<DCC_READ 0x17a115c4 1 0>,
				<DCC_READ 0x17a115dc 1 0>,
				<DCC_READ 0x17a115f4 1 0>,
				<DCC_READ 0x17a1160c 1 0>,
				<DCC_READ 0x17a11624 1 0>,
				<DCC_READ 0x17a1163c 1 0>,
				<DCC_READ 0x17a11654 1 0>,
				<DCC_READ 0x17a1166c 1 0>,
				<DCC_READ 0x17a11684 1 0>,
				<DCC_READ 0xc234004 5 0>,
				<DCC_LOOP 0x5 0 0>,
				<DCC_READ 0x17410000 6 0>,
				<DCC_READ 0x17411000 6 0>,
				<DCC_LOOP 0x1 0 0>,
				<DCC_READ 0x17d10200 320 0>,
				<DCC_READ 0x17120000 1 0>,
				<DCC_READ 0x17120008 1 0>,
				<DCC_READ 0x17120010 1 0>,
				<DCC_READ 0x17120018 1 0>,
				<DCC_READ 0x17120020 1 0>,
				<DCC_READ 0x17120028 1 0>,
				<DCC_READ 0x17120040 1 0>,
				<DCC_READ 0x17120048 1 0>,
				<DCC_READ 0x17120050 1 0>,
				<DCC_READ 0x17120058 1 0>,
				<DCC_READ 0x17120060 1 0>,
				<DCC_READ 0x17120068 1 0>,
				<DCC_READ 0x17120080 1 0>,
				<DCC_READ 0x17120088 1 0>,
				<DCC_READ 0x17120090 1 0>,
				<DCC_READ 0x17120098 1 0>,
				<DCC_READ 0x171200a0 1 0>,
				<DCC_READ 0x171200a8 1 0>,
				<DCC_READ 0x171200c0 1 0>,
				<DCC_READ 0x171200c8 1 0>,
				<DCC_READ 0x171200d0 1 0>,
				<DCC_READ 0x171200d8 1 0>,
				<DCC_READ 0x171200e0 1 0>,
				<DCC_READ 0x171200e8 1 0>,
				<DCC_READ 0x17120100 1 0>,
				<DCC_READ 0x17120108 1 0>,
				<DCC_READ 0x17120110 1 0>,
				<DCC_READ 0x17120118 1 0>,
				<DCC_READ 0x17120120 1 0>,
				<DCC_READ 0x17120128 1 0>,
				<DCC_READ 0x17120140 1 0>,
				<DCC_READ 0x17120148 1 0>,
				<DCC_READ 0x17120150 1 0>,
				<DCC_READ 0x17120158 1 0>,
				<DCC_READ 0x17120160 1 0>,
				<DCC_READ 0x17120168 1 0>,
				<DCC_READ 0x17120180 1 0>,
				<DCC_READ 0x17120188 1 0>,
				<DCC_READ 0x17120190 1 0>,
				<DCC_READ 0x17120198 1 0>,
				<DCC_READ 0x171201a0 1 0>,
				<DCC_READ 0x171201a8 1 0>,
				<DCC_READ 0x171201c0 1 0>,
				<DCC_READ 0x171201c8 1 0>,
				<DCC_READ 0x171201d0 1 0>,
				<DCC_READ 0x171201d8 1 0>,
				<DCC_READ 0x171201e0 1 0>,
				<DCC_READ 0x171201e8 1 0>,
				<DCC_READ 0x17120200 1 0>,
				<DCC_READ 0x17120208 1 0>,
				<DCC_READ 0x17120210 1 0>,
				<DCC_READ 0x17120218 1 0>,
				<DCC_READ 0x17120220 1 0>,
				<DCC_READ 0x17120228 1 0>,
				<DCC_READ 0x17120240 1 0>,
				<DCC_READ 0x17120248 1 0>,
				<DCC_READ 0x17120250 1 0>,
				<DCC_READ 0x17120258 1 0>,
				<DCC_READ 0x17120260 1 0>,
				<DCC_READ 0x17120268 1 0>,
				<DCC_READ 0x17120280 1 0>,
				<DCC_READ 0x17120288 1 0>,
				<DCC_READ 0x17120290 1 0>,
				<DCC_READ 0x17120298 1 0>,
				<DCC_READ 0x171202a0 1 0>,
				<DCC_READ 0x171202a8 1 0>,
				<DCC_READ 0x171202c0 1 0>,
				<DCC_READ 0x171202c8 1 0>,
				<DCC_READ 0x171202d0 1 0>,
				<DCC_READ 0x171202d8 1 0>,
				<DCC_READ 0x171202e0 1 0>,
				<DCC_READ 0x171202e8 1 0>,
				<DCC_READ 0x17120300 1 0>,
				<DCC_READ 0x17120308 1 0>,
				<DCC_READ 0x17120310 1 0>,
				<DCC_READ 0x17120318 1 0>,
				<DCC_READ 0x17120320 1 0>,
				<DCC_READ 0x17120328 1 0>,
				<DCC_READ 0x17120340 1 0>,
				<DCC_READ 0x17120348 1 0>,
				<DCC_READ 0x17120350 1 0>,
				<DCC_READ 0x17120358 1 0>,
				<DCC_READ 0x17120360 1 0>,
				<DCC_READ 0x17120368 1 0>,
				<DCC_READ 0x17120380 1 0>,
				<DCC_READ 0x17120388 1 0>,
				<DCC_READ 0x17120390 1 0>,
				<DCC_READ 0x17120398 1 0>,
				<DCC_READ 0x171203a0 1 0>,
				<DCC_READ 0x171203a8 1 0>,
				<DCC_READ 0x171203c0 1 0>,
				<DCC_READ 0x171203c8 1 0>,
				<DCC_READ 0x171203d0 1 0>,
				<DCC_READ 0x171203d8 1 0>,
				<DCC_READ 0x171203e0 1 0>,
				<DCC_READ 0x171203e8 1 0>,
				<DCC_READ 0x17120400 1 0>,
				<DCC_READ 0x17120408 1 0>,
				<DCC_READ 0x17120410 1 0>,
				<DCC_READ 0x17120418 1 0>,
				<DCC_READ 0x17120420 1 0>,
				<DCC_READ 0x17120428 1 0>,
				<DCC_READ 0x17120440 1 0>,
				<DCC_READ 0x17120448 1 0>,
				<DCC_READ 0x17120450 1 0>,
				<DCC_READ 0x17120458 1 0>,
				<DCC_READ 0x17120460 1 0>,
				<DCC_READ 0x17120468 1 0>,
				<DCC_READ 0x17120480 1 0>,
				<DCC_READ 0x17120488 1 0>,
				<DCC_READ 0x17120490 1 0>,
				<DCC_READ 0x17120498 1 0>,
				<DCC_READ 0x171204a0 1 0>,
				<DCC_READ 0x171204a8 1 0>,
				<DCC_READ 0x171204c0 1 0>,
				<DCC_READ 0x171204c8 1 0>,
				<DCC_READ 0x171204d0 1 0>,
				<DCC_READ 0x171204d8 1 0>,
				<DCC_READ 0x171204e0 1 0>,
				<DCC_READ 0x171204e8 1 0>,
				<DCC_READ 0x17120500 1 0>,
				<DCC_READ 0x17120508 1 0>,
				<DCC_READ 0x17120510 1 0>,
				<DCC_READ 0x17120518 1 0>,
				<DCC_READ 0x17120520 1 0>,
				<DCC_READ 0x17120528 1 0>,
				<DCC_READ 0x17120540 1 0>,
				<DCC_READ 0x17120548 1 0>,
				<DCC_READ 0x17120550 1 0>,
				<DCC_READ 0x17120558 1 0>,
				<DCC_READ 0x17120560 1 0>,
				<DCC_READ 0x17120568 1 0>,
				<DCC_READ 0x17120580 1 0>,
				<DCC_READ 0x17120588 1 0>,
				<DCC_READ 0x17120590 1 0>,
				<DCC_READ 0x17120598 1 0>,
				<DCC_READ 0x171205a0 1 0>,
				<DCC_READ 0x171205a8 1 0>,
				<DCC_READ 0x171205c0 1 0>,
				<DCC_READ 0x171205c8 1 0>,
				<DCC_READ 0x171205d0 1 0>,
				<DCC_READ 0x171205d8 1 0>,
				<DCC_READ 0x171205e0 1 0>,
				<DCC_READ 0x171205e8 1 0>,
				<DCC_READ 0x17120600 1 0>,
				<DCC_READ 0x17120608 1 0>,
				<DCC_READ 0x17120610 1 0>,
				<DCC_READ 0x17120618 1 0>,
				<DCC_READ 0x17120620 1 0>,
				<DCC_READ 0x17120628 1 0>,
				<DCC_READ 0x17120640 1 0>,
				<DCC_READ 0x17120648 1 0>,
				<DCC_READ 0x17120650 1 0>,
				<DCC_READ 0x17120658 1 0>,
				<DCC_READ 0x17120660 1 0>,
				<DCC_READ 0x17120668 1 0>,
				<DCC_READ 0x17120680 1 0>,
				<DCC_READ 0x17120688 1 0>,
				<DCC_READ 0x17120690 1 0>,
				<DCC_READ 0x17120698 1 0>,
				<DCC_READ 0x171206a0 1 0>,
				<DCC_READ 0x171206a8 1 0>,
				<DCC_READ 0x171206c0 1 0>,
				<DCC_READ 0x171206c8 1 0>,
				<DCC_READ 0x171206d0 1 0>,
				<DCC_READ 0x171206d8 1 0>,
				<DCC_READ 0x171206e0 1 0>,
				<DCC_READ 0x171206e8 1 0>,
				<DCC_READ 0x1712e000 1 0>,
				<DCC_READ 0x110004 1 0>,
				<DCC_READ 0x110008 1 0>,
				<DCC_READ 0x11003c 1 0>,
				<DCC_READ 0x110040 1 0>,
				<DCC_READ 0x110044 1 0>,
				<DCC_READ 0x17603c 1 0>,
				<DCC_READ 0x10c0000 4 0>,
				<DCC_READ 0x10c1000 2 0>,
				<DCC_READ 0x10c1010 7 0>,
				<DCC_READ 0x10c1100 3 0>,
				<DCC_READ 0x10c1110 5 0>,
				<DCC_READ 0x10c1130 2 0>,
				<DCC_READ 0x10c113c 2 0>,
				<DCC_READ 0x10c1148 3 0>,
				<DCC_READ 0x10c2000 1 0>,
				<DCC_READ 0x10cf004 1 0>,
				<DCC_READ 0x110018 7 0>,
				<DCC_READ 0x11c018 7 0>,
				<DCC_READ 0x178040 1 0>,
				<DCC_READ 0x199014 7 0>,
				<DCC_READ 0x19d014 7 0>,
				<DCC_READ 0x110040 7 0>,
				<DCC_READ 0x110064 1 0>,
				<DCC_READ 0x110070 2 0>,
				<DCC_READ 0x111004 2 0>,
				<DCC_READ 0x16b018 3 0>,
				<DCC_READ 0x16b02c 1 0>,
				<DCC_READ 0x16b038 2 0>,
				<DCC_READ 0x16b048 1 0>,
				<DCC_READ 0x16b054 1 0>,
				<DCC_READ 0x16b098 1 0>,
				<DCC_READ 0x1c00000 1 0>,
				<DCC_READ 0x1c00024 2 0>,
				<DCC_READ 0x1c001b0 1 0>,
				<DCC_READ 0x1c001b0 1 0>,
				<DCC_READ 0x1c00224 1 0>,
				<DCC_READ 0x1c00230 1 0>,
				<DCC_READ 0x1c002b0 1 0>,
				<DCC_READ 0x1c003c0 1 0>,
				<DCC_READ 0x1c004d0 2 0>,
				<DCC_READ 0x1c00500 1 0>,
				<DCC_READ 0x1c00630 1 0>,
				<DCC_READ 0x1c061c8 8 0>,
				<DCC_READ 0x1c061f8 1 0>,
				<DCC_READ 0x1c06214 1 0>,
				<DCC_READ 0x1c06214 11 0>,
				<DCC_READ 0x1c06600 2 0>,
				<DCC_READ 0x1c06804 1 0>,
				<DCC_READ 0x1c06a00 4 0>,
				<DCC_READ 0x1c06a18 1 0>,
				<DCC_READ 0x1c06c20 1 0>,
				<DCC_READ 0x1c07204 1 0>,
				<DCC_READ 0x1c076d0 1 0>,
				<DCC_READ 0x1c076dc 1 0>,
				<DCC_READ 0x1c07734 11 0>,
				<DCC_READ 0x1ff1100 1 0>,
				<DCC_READ 0x60000080 1 0>,
				<DCC_READ 0x60000104 1 0>,
				<DCC_READ 0x60000110 1 0>,
				<DCC_READ 0x60000204 1 0>,
				<DCC_READ 0x60000730 4 0>,
				<DCC_READ 0x17421000 2 0>;
		};

		link_list_2 {
			qcom,curr-link-list = <2>;
			qcom,data-sink = "sram";
			qcom,ap-qad-override;
			qcom,link-list = <DCC_READ 0x0c222004 1 0>,
				<DCC_READ 0x0c228014 1 0>,
				<DCC_READ 0x0c2280e0 1 0>,
				<DCC_READ 0x0c2280ec 1 0>,
				<DCC_READ 0x0c2280a0 16 0>,
				<DCC_READ 0x0c2280e8 1 0>,
				<DCC_READ 0x0c22813c 1 0>,
				<DCC_READ 0x0c223004 1 0>,
				<DCC_READ 0x0c229014 1 0>,
				<DCC_READ 0x0c2290e0 1 0>,
				<DCC_READ 0x0c2290ec 1 0>,
				<DCC_READ 0x0c2290a0 16 0>,
				<DCC_READ 0x0c2290e8 1 0>,
				<DCC_READ 0x0c22913c 1 0>,
				<DCC_READ 0x0c224004 1 0>,
				<DCC_READ 0x0c22a014 1 0>,
				<DCC_READ 0x0c22a0e0 1 0>,
				<DCC_READ 0x0c22a0ec 1 0>,
				<DCC_READ 0x0c22a0a0 16 0>,
				<DCC_READ 0x0c22a0e8 1 0>,
				<DCC_READ 0x0c22a13c 1 0>,
				<DCC_READ 0xec80010 1 0>,
				<DCC_READ 0xec81000 1 0>,
				<DCC_READ 0xec81010 161 0>,
				<DCC_READ 0xec81050 16 0>,
				<DCC_READ 0xec81090 16 0>,
				<DCC_READ 0xec810d0 16 0>,
				<DCC_READ 0xec81110 16 0>,
				<DCC_READ 0xec81150 16 0>,
				<DCC_READ 0xec81550 1 0>,
				<DCC_READ 0x17b70220 6 0>,
				<DCC_READ 0x17b702a0 6 0>,
				<DCC_READ 0x17b70320 1 0>,
				<DCC_READ 0x17b704a0 16 0>,
				<DCC_READ 0x17b70520 1 0>,
				<DCC_READ 0x17b70524 1 0>,
				<DCC_READ 0x17b70588 1 0>,
				<DCC_READ 0x17b70630 2 0>,
				<DCC_READ 0x17b70638 2 0>,
				<DCC_READ 0x17b70640 2 0>,
				<DCC_READ 0x17b71010 24 0>,
				<DCC_READ 0x17b71310 16 0>,
				<DCC_READ 0x17b71390 16 0>,
				<DCC_READ 0x17b72090 8 0>,
				<DCC_READ 0x17b784a0 12 0>,
				<DCC_READ 0x17b78520 1 0>,
				<DCC_READ 0x17b78588 1 0>,
				<DCC_READ 0x17b78630 2 0>,
				<DCC_READ 0x17b78638 2 0>,
				<DCC_READ 0x17b78640 2 0>,
				<DCC_READ 0x17b79010 8 0>,
				<DCC_READ 0x17b79310 6 0>,
				<DCC_READ 0x17b79390 6 0>,
				<DCC_READ 0x17b7a090 4 0>,
				<DCC_READ 0x32310220 4 0>,
				<DCC_READ 0x323102a0 4 0>,
				<DCC_READ 0x323104a0 6 0>,
				<DCC_READ 0x32310520 1 0>,
				<DCC_READ 0x32310588 1 0>,
				<DCC_READ 0x32310630 2 0>,
				<DCC_READ 0x32310638 2 0>,
				<DCC_READ 0x32310640 2 0>,
				<DCC_READ 0x32311010 8 0>,
				<DCC_READ 0x32311310 6 0>,
				<DCC_READ 0x32311390 6 0>,
				<DCC_READ 0x32312090 3 0>,
				<DCC_READ 0x240e0008 1 0>,
				<DCC_READ 0x240e0010 1 0>,
				<DCC_READ 0x240e0020 8 0>,
				<DCC_READ 0x240e0240 1 0>,
				<DCC_READ 0x240e0248 1 0>,
				<DCC_READ 0x245f0008 1 0>,
				<DCC_READ 0x245f0010 1 0>,
				<DCC_READ 0x245f0020 8 0>,
				<DCC_READ 0x245f0240 1 0>,
				<DCC_READ 0x245f0248 1 0>,
				<DCC_READ 0x247f0008 1 0>,
				<DCC_READ 0x247f0010 1 0>,
				<DCC_READ 0x247f0020 8 0>,
				<DCC_READ 0x247f0240 1 0>,
				<DCC_READ 0x247f0248 1 0>,
				<DCC_READ 0x24330008 1 0>,
				<DCC_READ 0x24330010 1 0>,
				<DCC_READ 0x24330020 8 0>,
				<DCC_READ 0x24330240 1 0>,
				<DCC_READ 0x24330248 1 0>,
				<DCC_READ 0x24347040 1 0>,
				<DCC_READ 0x24347048 1 0>,
				<DCC_READ 0x240e1018 1 0>,
				<DCC_READ 0x240e1008 1 0>,
				<DCC_LOOP 0x7 0 0>,
				<DCC_READ 0x240e1010 2 0>,
				<DCC_LOOP 0x1 0 0>,
				<DCC_READ 0x245f2018 1 0>,
				<DCC_READ 0x245f2008 1 0>,
				<DCC_LOOP 0x2 0 0>,
				<DCC_READ 0x245f2010 2 0>,
				<DCC_LOOP 0x1 0 0>,
				<DCC_READ 0x247f2018 1 0>,
				<DCC_READ 0x247f2008 1 0>,
				<DCC_LOOP 0x2 0 0>,
				<DCC_READ 0x247f2010 2 0>,
				<DCC_LOOP 0x1 0 0>,
				<DCC_READ 0x24331018 1 0>,
				<DCC_READ 0x24331008 1 0>,
				<DCC_LOOP 0x6 0 0>,
				<DCC_READ 0x24331010 2 0>,
				<DCC_LOOP 0x1 0 0>,
				<DCC_READ 0x24341008 1 0>,
				<DCC_READ 0x24341010 3 0>;
		};
	};

	mem_dump {
		compatible = "qcom,mem-dump";
		memory-region = <&dump_mem>;

		c0_context {
			qcom,dump-size = <0x800>;
			qcom,dump-id = <0x0>;
		};

		c100_context {
			qcom,dump-size = <0x800>;
			qcom,dump-id = <0x1>;
		};

		c200_context {
			qcom,dump-size = <0x800>;
			qcom,dump-id = <0x2>;
		};

		c300_context {
			qcom,dump-size = <0x800>;
			qcom,dump-id = <0x3>;
		};

		c400_context {
			qcom,dump-size = <0x800>;
			qcom,dump-id = <0x4>;
		};

		c500_context {
			qcom,dump-size = <0x800>;
			qcom,dump-id = <0x5>;
		};

		c600_context {
			qcom,dump-size = <0x800>;
			qcom,dump-id = <0x6>;
		};

		c700_context {
			qcom,dump-size = <0x800>;
			qcom,dump-id = <0x7>;
		};

		l1_icache0 {
			qcom,dump-size = <0x22100>;
			qcom,dump-id = <0x60>;
		};

		l1_icache100 {
			qcom,dump-size = <0x22100>;
			qcom,dump-id = <0x61>;
		};

		l1_icache200 {
			qcom,dump-size = <0x22100>;
			qcom,dump-id = <0x62>;
		};

		l1_icache300 {
			qcom,dump-size = <0x22100>;
			qcom,dump-id = <0x63>;
		};

		l1_icache400 {
			qcom,dump-size = <0x22100>;
			qcom,dump-id = <0x64>;
		};

		l1_icache500 {
			qcom,dump-size = <0x22100>;
			qcom,dump-id = <0x65>;
		};

		l1_icache600 {
			qcom,dump-size = <0x22100>;
			qcom,dump-id = <0x66>;
		};

		l1_icache700 {
			qcom,dump-size = <0x22100>;
			qcom,dump-id = <0x67>;
		};

		l1_dcache0 {
			qcom,dump-size = <0x12100>;
			qcom,dump-id = <0x80>;
		};

		l1_dcache100 {
			qcom,dump-size = <0x12100>;
			qcom,dump-id = <0x81>;
		};

		l1_dcache200 {
			qcom,dump-size = <0x1a100>;
			qcom,dump-id = <0x82>;
		};

		l1_dcache300 {
			qcom,dump-size = <0x1a100>;
			qcom,dump-id = <0x83>;
		};

		l1_dcache400 {
			qcom,dump-size = <0x1a100>;
			qcom,dump-id = <0x84>;
		};

		l1_dcache500 {
			qcom,dump-size = <0x1a100>;
			qcom,dump-id = <0x85>;
		};

		l1_dcache600 {
			qcom,dump-size = <0x1a100>;
			qcom,dump-id = <0x86>;
		};

		l1_dcache700 {
			qcom,dump-size = <0x1a100>;
			qcom,dump-id = <0x87>;
		};

		l1_itlb700 {
			qcom,dump-size = <0x600>;
			qcom,dump-id = <0x27>;
		};

		l1_dtlb700 {
			qcom,dump-size = <0xa00>;
			qcom,dump-id = <0x47>;
		};

		l2_cache0 {
			qcom,dump-size = <0x90100>;
			qcom,dump-id = <0xc0>;
		};

		l2_cache100 {
			qcom,dump-size = <0x90100>;
			qcom,dump-id = <0xc1>;
		};

		l2_cache200 {
			qcom,dump-size = <0xd0100>;
			qcom,dump-id = <0xc2>;
		};

		l2_cache300 {
			qcom,dump-size = <0xd0100>;
			qcom,dump-id = <0xc3>;
		};

		l2_cache400 {
			qcom,dump-size = <0xd0100>;
			qcom,dump-id = <0xc4>;
		};

		l2_cache500 {
			qcom,dump-size = <0xd0100>;
			qcom,dump-id = <0xc5>;
		};

		l2_cache600 {
			qcom,dump-size = <0xd0100>;
			qcom,dump-id = <0xc6>;
		};

		l2_cache700 {
			qcom,dump-size = <0x340100>;
			qcom,dump-id = <0xc7>;
		};

		l2_tlb0 {
			qcom,dump-size = <0xf700>;
			qcom,dump-id = <0x120>;
		};

		l2_tlb100 {
			qcom,dump-size = <0xf700>;
			qcom,dump-id = <0x121>;
		};

		l2_tlb700 {
			qcom,dump-size = <0xa900>;
			qcom,dump-id = <0x127>;
		};

		l1dcdirty0 {
			qcom,dump-size = <0x2100>;
			qcom,dump-id = <0x170>;
		};

		l1dcdirty100 {
			qcom,dump-size = <0x2100>;
			qcom,dump-id = <0x171>;
		};

		l1dcmte0 {
			qcom,dump-size = <0x2100>;
			qcom,dump-id = <0x180>;
		};

		l1dcmte100 {
			qcom,dump-size = <0x2100>;
			qcom,dump-id = <0x181>;
		};

		l2dcmte0 {
			qcom,dump-size = <0x10100>;
			qcom,dump-id = <0x190>;
		};

		l2dcmte100 {
			qcom,dump-size = <0x10100>;
			qcom,dump-id = <0x191>;
		};

		l0mopca700 {
			qcom,dump-size = <0x4100>;
			qcom,dump-id = <0x1a7>;
		};

		l2victim700 {
			qcom,dump-size = <0x2100>;
			qcom,dump-id = <0x1e7>;
		};

		l2tldtcsp200 {
			qcom,dump-size = <0x7900>;
			qcom,dump-id = <0x202>;
		};

		l2tldtcsp300 {
			qcom,dump-size = <0x7900>;
			qcom,dump-id = <0x203>;
		};

		l2tldtcsp400 {
			qcom,dump-size = <0x7900>;
			qcom,dump-id = <0x204>;
		};

		l2tldtcsp500 {
			qcom,dump-size = <0x7900>;
			qcom,dump-id = <0x205>;
		};

		l2tldtcsp600 {
			qcom,dump-size = <0x7900>;
			qcom,dump-id = <0x206>;
		};

		l2tldtcmp200 {
			qcom,dump-size = <0x1300>;
			qcom,dump-id = <0x212>;
		};

		l2tldtcmp300 {
			qcom,dump-size = <0x1300>;
			qcom,dump-id = <0x213>;
		};

		l2tldtcmp400 {
			qcom,dump-size = <0x1300>;
			qcom,dump-id = <0x214>;
		};

		l2tldtcmp500 {
			qcom,dump-size = <0x1300>;
			qcom,dump-id = <0x215>;
		};

		l2tldtcmp600 {
			qcom,dump-size = <0x1300>;
			qcom,dump-id = <0x216>;
		};

		cpuss_reg {
			qcom,dump-size = <0x36000>;
			qcom,dump-id = <0xef>;
		};

		rpmh {
			qcom,dump-size = <0x400000>;
			qcom,dump-id = <0xec>;
		};

		rpm_sw {
			qcom,dump-size = <0x28000>;
			qcom,dump-id = <0xea>;
		};

		pmic {
			qcom,dump-size = <0x200000>;
			qcom,dump-id = <0xe4>;
		};

		fcm {
			qcom,dump-size = <0x8400>;
			qcom,dump-id = <0xee>;
		};

		etf_swao {
			qcom,dump-size = <0x10000>;
			qcom,dump-id = <0xf1>;
		};

		etr_reg {
			qcom,dump-size = <0x1000>;
			qcom,dump-id = <0x100>;
		};

		etfswao_reg {
			qcom,dump-size = <0x1000>;
			qcom,dump-id = <0x102>;
		};

		etr1_reg {
			qcom,dump-size = <0x1000>;
			qcom,dump-id = <0x105>;
		};

		misc_data {
			qcom,dump-size = <0x1000>;
			qcom,dump-id = <0xe8>;
		};

		etf_slpi {
			qcom,dump-size = <0x4000>;
			qcom,dump-id = <0xf3>;
		};

		etfslpi_reg {
			qcom,dump-size = <0x1000>;
			qcom,dump-id = <0x103>;
		};

		etf_lpass {
			qcom,dump-size = <0x4000>;
			qcom,dump-id = <0xf4>;
		};

		etflpass_reg {
			qcom,dump-size = <0x1000>;
			qcom,dump-id = <0x104>;
		};

		osm_reg {
			qcom,dump-size = <0x400>;
			qcom,dump-id = <0x163>;
		};

		pcu_reg {
			qcom,dump-size = <0x400>;
			qcom,dump-id = <0x164>;
		};

		fsm_data {
			qcom,dump-size = <0x400>;
			qcom,dump-id = <0x165>;
		};

		spr_cpu0 {
			qcom,dump-size = <0x2000>;
			qcom,dump-id = <0x1f0>;
		};

		spr_cpu1 {
			qcom,dump-size = <0x2000>;
			qcom,dump-id = <0x1f1>;
		};

		spr_cpu2 {
			qcom,dump-size = <0x2000>;
			qcom,dump-id = <0x1f2>;
		};

		spr_cpu3 {
			qcom,dump-size = <0x2000>;
			qcom,dump-id = <0x1f3>;
		};

		spr_cpu4 {
			qcom,dump-size = <0x2000>;
			qcom,dump-id = <0x1f4>;
		};

		spr_cpu5 {
			qcom,dump-size = <0x2000>;
			qcom,dump-id = <0x1f5>;
		};

		spr_cpu6 {
			qcom,dump-size = <0x2000>;
			qcom,dump-id = <0x1f6>;
		};

		spr_cpu7 {
			qcom,dump-size = <0x2000>;
			qcom,dump-id = <0x1f7>;
		};

		scandump_smmu {
			qcom,dump-size = <0x40000>;
			qcom,dump-id = <0x220>;
		};

		scandump_gpu {
			qcom,dump-size = <0x300000>;
			qcom,dump-id = <0x221>;
		};
	};
};
